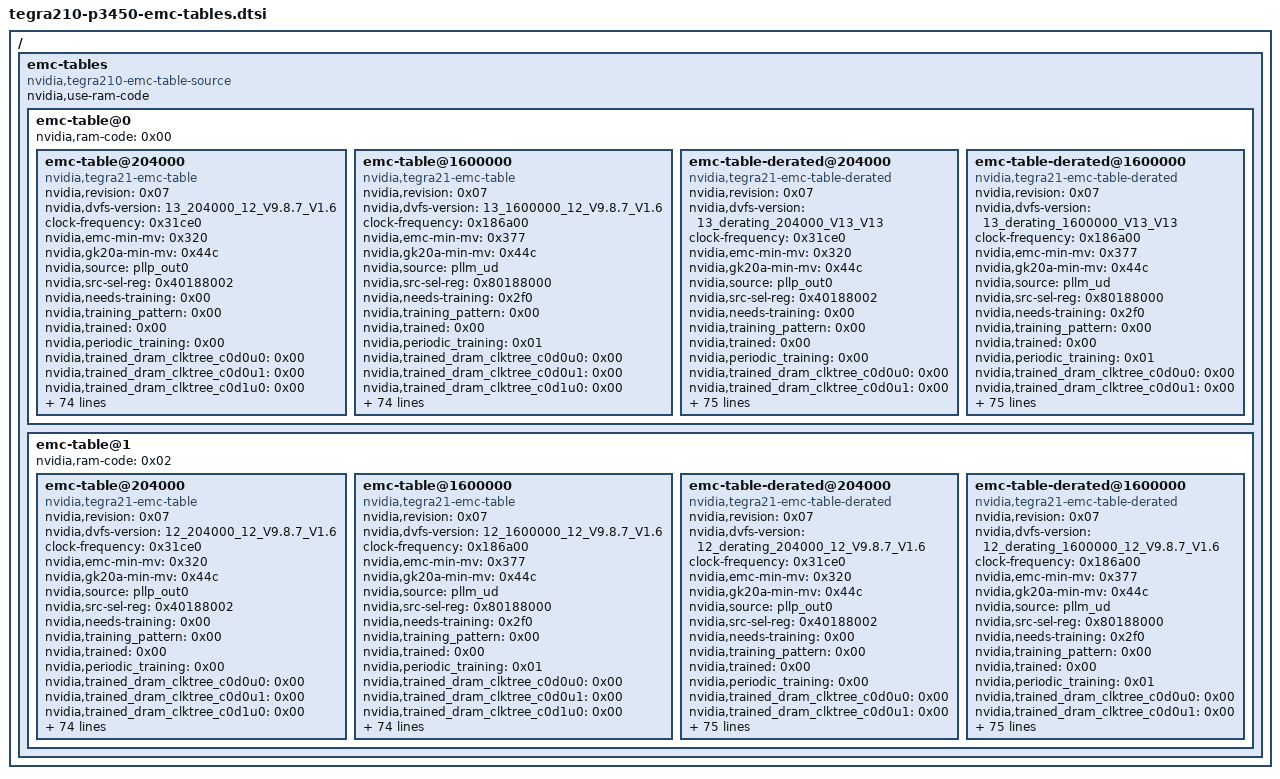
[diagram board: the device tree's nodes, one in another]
// SPDX-License-Identifier: GPL-2.0+
/*
 * Jetson Nano (P3450) EMC frequency tables, extracted verbatim from NVIDIA's
 * bl-dtb (the proprietary rp1 blob that cboot loads).  Carried in U-Boot's
 * control DTB so that, under the RAM-boot flow (cboot bypassed), U-Boot can
 * synthesize the binary EMC timing table the mainline tegra210-emc driver
 * expects and inject it + its reserved-memory carveout into the kernel DTB --
 * exactly what cboot does on a normal boot.  See board/nvidia/p3450-0000/emc-table.c.
 *
 * Nothing here is hand-authored: the emc-table@{0,1} subtrees (nominal +
 * derated, ram-code 0 and 2, each 204 MHz + 1600 MHz) are copied unchanged
 * from the stock bl-dtb.
 */

/ {
	emc-tables {
		compatible = "nvidia,tegra210-emc-table-source";
		nvidia,use-ram-code;

		emc-table@0 {
			nvidia,ram-code = <0x00>;

			emc-table@204000 {
				compatible = "nvidia,tegra21-emc-table";
				nvidia,revision = <0x07>;
				nvidia,dvfs-version = "13_204000_12_V9.8.7_V1.6";
				clock-frequency = <0x31ce0>;
				nvidia,emc-min-mv = <0x320>;
				nvidia,gk20a-min-mv = <0x44c>;
				nvidia,source = "pllp_out0";
				nvidia,src-sel-reg = <0x40188002>;
				nvidia,needs-training = <0x00>;
				nvidia,training_pattern = <0x00>;
				nvidia,trained = <0x00>;
				nvidia,periodic_training = <0x00>;
				nvidia,trained_dram_clktree_c0d0u0 = <0x00>;
				nvidia,trained_dram_clktree_c0d0u1 = <0x00>;
				nvidia,trained_dram_clktree_c0d1u0 = <0x00>;
				nvidia,trained_dram_clktree_c0d1u1 = <0x00>;
				nvidia,trained_dram_clktree_c1d0u0 = <0x00>;
				nvidia,trained_dram_clktree_c1d0u1 = <0x00>;
				nvidia,trained_dram_clktree_c1d1u0 = <0x00>;
				nvidia,trained_dram_clktree_c1d1u1 = <0x00>;
				nvidia,current_dram_clktree_c0d0u0 = <0x00>;
				nvidia,current_dram_clktree_c0d0u1 = <0x00>;
				nvidia,current_dram_clktree_c0d1u0 = <0x00>;
				nvidia,current_dram_clktree_c0d1u1 = <0x00>;
				nvidia,current_dram_clktree_c1d0u0 = <0x00>;
				nvidia,current_dram_clktree_c1d0u1 = <0x00>;
				nvidia,current_dram_clktree_c1d1u0 = <0x00>;
				nvidia,current_dram_clktree_c1d1u1 = <0x00>;
				nvidia,run_clocks = <0x0d>;
				nvidia,tree_margin = <0x01>;
				nvidia,burst-regs-num = <0xdd>;
				nvidia,burst-regs-per-ch-num = <0x08>;
				nvidia,trim-regs-num = <0x8a>;
				nvidia,trim-regs-per-ch-num = <0x0a>;
				nvidia,burst-mc-regs-num = <0x21>;
				nvidia,la-scale-regs-num = <0x18>;
				nvidia,vref-regs-num = <0x04>;
				nvidia,training-mod-regs-num = <0x14>;
				nvidia,dram-timing-regs-num = <0x05>;
				nvidia,min-mrs-wait = <0x16>;
				nvidia,emc-mrw = <0x88010004>;
				nvidia,emc-mrw2 = <0x88020000>;
				nvidia,emc-mrw3 = <0x880d0000>;
				nvidia,emc-mrw4 = <0xc0000000>;
				nvidia,emc-mrw9 = <0x8c0e7272>;
				nvidia,emc-mrs = <0x00>;
				nvidia,emc-emrs = <0x00>;
				nvidia,emc-emrs2 = <0x00>;
				nvidia,emc-auto-cal-config = <0xa01a51d8>;
				nvidia,emc-auto-cal-config2 = <0x5500000>;
				nvidia,emc-auto-cal-config3 = <0x770000>;
				nvidia,emc-auto-cal-config4 = <0x770000>;
				nvidia,emc-auto-cal-config5 = <0x770000>;
				nvidia,emc-auto-cal-config6 = <0x770000>;
				nvidia,emc-auto-cal-config7 = <0x770000>;
				nvidia,emc-auto-cal-config8 = <0x770000>;
				nvidia,emc-cfg-2 = <0x110805>;
				nvidia,emc-sel-dpd-ctrl = <0x40008>;
				nvidia,emc-fdpd-ctrl-cmd-no-ramp = <0x01>;
				nvidia,dll-clk-src = <0x40188002>;
				nvidia,clk-out-enb-x-0-clk-enb-emc-dll = <0x01>;
				nvidia,emc-clock-latency-change = <0xd5c>;
				nvidia,ptfv = <0x00 0x00 0x00 0x00 0x00 0x00 0x00 0x00 0x0a 0x0a 0x0a 0x01>;
				nvidia,emc-registers = <0x0d 0x3a 0x1d 0x00 0x00 0x09 0x04 0x0b 0x0d 0x08 0x0b 0x00 0x04 0x20 0x06 0x06 0x06 0x03 0x00 0x06 0x04 0x02 0x00 0x04 0x08 0x0d 0x06 0x05 0x00 0x00 0x03 0x88037171 0x0c 0x01 0x0a 0x10000 0x12 0x14 0x16 0x12 0x14 0x304 0x00 0xc1 0x08 0x08 0x03 0x03 0x03 0x14 0x05 0x02 0x0d 0x3b 0x3b 0x05 0x05 0x04 0x09 0x05 0x04 0x09 0xc8037171 0x31c 0x00 0x9160a00d 0x3bbf 0x2c00a0 0x8000 0xbe 0xfff0fff 0xfff0fff 0x00 0x00 0x00 0x00 0x880b0000 0xe0017 0x1c0014 0x450031 0x3f002b 0x3d0028 0x3d0031 0x0b 0x100004 0x450031 0x3f002b 0x3d0028 0x3d0031 0x0b 0x100004 0x170017 0xe000e 0x140014 0x1c001c 0x17 0x00 0x00 0x00 0x00 0x00 0x00 0x00 0x00 0x00 0x00 0x00 0x00 0x00 0x00 0x00 0x00 0x00 0x00 0x00 0x00 0x00 0x00 0x00 0x00 0x00 0x00 0x00 0x00 0x00 0x00 0x00 0x00 0x00 0x00 0x00 0x00 0x00 0x00 0x00 0x00 0x8020221f 0x220f40f 0x12 0x64000 0x900cc 0xcc0016 0x33000a 0xc1e00303 0x1f13412f 0x10014 0x804 0x550 0xf3200000 0xfff0fff 0x713 0x0a 0x00 0x00 0x1b 0x1b 0x20000 0x50037 0x00 0x10 0x3000 0xa000000 0x2000111 0x08 0x30808 0x15c00 0x101010 0x1600 0x00 0x00 0x00 0x34 0x40 0x18000800 0x8000800 0x8000800 0x8000800 0x400080 0x8801004 0x20 0x00 0x00 0x00 0x00 0x00 0x00 0xefffefff 0xc0c0c0c0 0xc0c0c0c0 0xdcdcdcdc 0xa0a0a0a 0xa0a0a0a 0xa0a0a0a 0x1186033 0x00 0x00 0x14 0x0a 0x16 0x88161414 0x12 0x10000 0x9080 0x7070404 0x40065 0x513801f 0x1f101100 0x14 0x107240 0x1124000 0x1125b6a 0xf081000 0x105800 0x1110fc00 0xf081300 0x105800 0x1114fc00 0x7000300 0x107240 0x55553c5a 0xc8161414>;
				nvidia,emc-burst-regs-per-ch = <0x880c7272 0x880c7272 0xc80c7272 0xc80c7272 0x8c0e7272 0x8c0e7272 0x4c0e7272 0x4c0e7272>;
				nvidia,emc-shadow-regs-ca-train = <0x0d 0x3a 0x1d 0x00 0x00 0x09 0x04 0x0b 0x0d 0x08 0x0b 0x00 0x04 0x20 0x06 0x06 0x06 0x03 0x00 0x06 0x04 0x02 0x00 0x04 0x08 0x0d 0x06 0x05 0x00 0x00 0x03 0x88037171 0x0c 0x01 0x0a 0x10000 0x12 0x14 0x16 0x12 0x14 0x304 0x00 0xc1 0x08 0x08 0x03 0x03 0x03 0x14 0x05 0x02 0x0d 0x3b 0x3b 0x05 0x05 0x04 0x09 0x05 0x04 0x09 0xc8037171 0x31c 0x00 0x9960a00d 0x3bbf 0x2c00a0 0x8000 0x55 0xfff0fff 0xfff0fff 0x00 0x00 0x00 0x00 0x880b0000 0xe0017 0x1c0014 0x450031 0x3f002b 0x3d0028 0x3d0031 0x0b 0x100004 0x450031 0x3f002b 0x3d0028 0x3d0031 0x0b 0x100004 0x170017 0xe000e 0x140014 0x1c001c 0x17 0x00 0x00 0x00 0x00 0x00 0x00 0x00 0x00 0x00 0x00 0x00 0x00 0x00 0x00 0x00 0x00 0x00 0x00 0x00 0x00 0x00 0x00 0x00 0x00 0x00 0x00 0x00 0x00 0x00 0x00 0x00 0x00 0x00 0x00 0x00 0x00 0x00 0x00 0x00 0x00 0x8020221f 0x220f40f 0x12 0x64000 0x900cc 0xcc0016 0x33000a 0xc1e00303 0x1f13412f 0x10014 0x804 0x550 0xf3200000 0xfff0fff 0x713 0x0a 0x00 0x00 0x1b 0x1b 0x20000 0x5058033 0x5050000 0x00 0x3000 0xa000000 0x2000111 0x08 0x30808 0x15c00 0x101010 0x1600 0x00 0x00 0x00 0x34 0x40 0x18000800 0x8000800 0x8000800 0x8000800 0x400080 0x8801004 0x20 0x00 0x00 0x00 0x00 0x00 0x00 0xefffefff 0xc0c0c0c0 0xc0c0c0c0 0xdcdcdcdc 0xa0a0a0a 0xa0a0a0a 0xa0a0a0a 0x1186033 0x01 0x1f 0x18 0x08 0x1a 0x88161414 0x10 0x10000 0x9080 0x7070404 0x40065 0x513801f 0x1f101100 0x14 0x107240 0x1124000 0x1125b6a 0xf081000 0x105800 0x1110fc00 0xf081300 0x105800 0x1114fc00 0x7000300 0x107240 0x55553c5a 0xc8161414>;
				nvidia,emc-shadow-regs-quse-train = <0x0d 0x3a 0x1d 0x00 0x00 0x09 0x04 0x0a 0x0d 0x08 0x0b 0x00 0x04 0x20 0x06 0x06 0x06 0x0c 0x00 0x06 0x04 0x02 0x00 0x04 0x08 0x0d 0x03 0x02 0x10000000 0x00 0x03 0x88037171 0x0b 0x01 0x80000000 0x40000 0x12 0x14 0x16 0x12 0x14 0x304 0x00 0xc1 0x08 0x08 0x03 0x03 0x03 0x14 0x05 0x02 0x0d 0x3b 0x3b 0x05 0x05 0x04 0x09 0x05 0x04 0x09 0xc8037171 0x31c 0x00 0x9160400d 0x3bbf 0x2c00a0 0x8000 0xbe 0xfff0fff 0xfff0fff 0x00 0x00 0x00 0x00 0x880b0000 0xe0017 0x1c0014 0x450031 0x3f002b 0x3d0028 0x3d0031 0x0b 0x100004 0x450031 0x3f002b 0x3d0028 0x3d0031 0x0b 0x100004 0x170017 0xe000e 0x140014 0x1c001c 0x17 0x00 0x00 0x00 0x00 0x00 0x00 0x00 0x00 0x00 0x00 0x00 0x00 0x00 0x00 0x00 0x00 0x00 0x00 0x00 0x00 0x00 0x00 0x00 0x00 0x00 0x00 0x00 0x00 0x00 0x00 0x00 0x00 0x00 0x00 0x00 0x00 0x00 0x00 0x00 0x00 0x8020221f 0x220f40f 0x12 0x64000 0x900cc 0xcc0016 0x33000a 0xc1e00303 0x1f13412f 0x10014 0x804 0x550 0xf3200000 0xfff0fff 0x713 0x0a 0x00 0x00 0x1b 0x1b 0x30020000 0x58037 0x00 0x10 0x3000 0xa000000 0x2000111 0x08 0x30808 0x15c00 0x101010 0x1600 0x00 0x00 0x00 0x34 0x40 0x18000800 0x8000800 0x8000800 0x8000800 0x400080 0x8801004 0x20 0x00 0x00 0x00 0x00 0x00 0x00 0xefffefff 0xc0c0c0c0 0xc0c0c0c0 0xdcdcdcdc 0xa0a0a0a 0xa0a0a0a 0xa0a0a0a 0x1186033 0x01 0x1f 0x1e 0x14 0x20 0x88161414 0x1c 0x40000 0x9080 0x7070404 0x40065 0x513801f 0x1f101100 0x14 0x107240 0x1124000 0x1125b6a 0xf081000 0x105800 0x1110fc00 0xf081300 0x105800 0x1114fc00 0x7000300 0x107240 0x55553c5a 0xc8161414>;
				nvidia,emc-shadow-regs-rdwr-train = <0x0d 0x3a 0x1d 0x00 0x00 0x09 0x04 0x0e 0x0d 0x08 0x0b 0x00 0x04 0x20 0x06 0x06 0x06 0x12 0x13 0x06 0x04 0x02 0x00 0x04 0x08 0x0d 0x06 0x05 0x10000000 0x30000002 0x03 0x88037171 0x0c 0x01 0x0a 0x40000 0x12 0x14 0x16 0x12 0x14 0x304 0x00 0xc1 0x08 0x08 0x03 0x03 0x03 0x14 0x05 0x02 0x0d 0x3b 0x3b 0x05 0x05 0x04 0x09 0x05 0x04 0x09 0xc8037171 0x31c 0x00 0x9160a00d 0x3bbf 0x2c00a0 0x8000 0xbe 0xfff0fff 0xfff0fff 0x00 0x00 0x00 0x00 0x880b0000 0xe0017 0x1c0014 0x450031 0x3f002b 0x3d0028 0x3d0031 0x0b 0x100004 0x450031 0x3f002b 0x3d0028 0x3d0031 0x0b 0x100004 0x170017 0xe000e 0x140014 0x1c001c 0x17 0x00 0x00 0x00 0x00 0x00 0x00 0x00 0x00 0x00 0x00 0x00 0x00 0x00 0x00 0x00 0x00 0x00 0x00 0x00 0x00 0x00 0x00 0x00 0x00 0x00 0x00 0x00 0x00 0x00 0x00 0x00 0x00 0x00 0x00 0x00 0x00 0x00 0x00 0x00 0x00 0x8020221f 0x220f40f 0x12 0x64000 0x900cc 0xcc0016 0x33000a 0xc1e00303 0x1f13412f 0x10014 0x804 0x550 0xf3200000 0xfff0fff 0x713 0x0a 0x00 0x00 0x1b 0x1b 0x20000 0x50037 0x00 0x10 0x3000 0xa000000 0x2000111 0x08 0x30808 0x15c00 0x101010 0x1600 0x00 0x00 0x00 0x34 0x40 0x18000800 0x8000800 0x8000800 0x8000800 0x400080 0x8801004 0x20 0x00 0x00 0x00 0x00 0x00 0x00 0xefffefff 0xc0c0c0c0 0xc0c0c0c0 0xdcdcdcdc 0xa0a0a0a 0xa0a0a0a 0xa0a0a0a 0x1186033 0x01 0x00 0x14 0x0a 0x16 0x88161414 0x12 0x40000 0xb080 0x7070404 0x40065 0x513801f 0x1f101100 0x14 0x107240 0x1124000 0x1125b6a 0xf081000 0x105800 0x1110fc00 0xf081300 0x105800 0x1114fc00 0x7000300 0x107240 0x55553c5a 0xc8161414>;
				nvidia,emc-trim-regs = <0x280028 0x280028 0x280028 0x280028 0x280028 0x280028 0x280028 0x280028 0x00 0x00 0x00 0x00 0x00 0x00 0x00 0x00 0x00 0x00 0x00 0x00 0x00 0x00 0x00 0x00 0x00 0x00 0x00 0x00 0x00 0x00 0x00 0x00 0x00 0x00 0x00 0x00 0x00 0x00 0x00 0x00 0x00 0x00 0x00 0x00 0x00 0x00 0x00 0x00 0x00 0x00 0x00 0x00 0x00 0x00 0x00 0x00 0x11111111 0x11111111 0x28282828 0x28282828 0x00 0x00 0x00 0x00 0xe0017 0x1c0014 0x00 0x00 0x00 0x00 0x00 0x00 0x00 0x00 0x00 0x00 0x00 0x00 0x00 0x00 0x00 0x00 0x00 0x00 0x00 0x00 0x00 0x00 0x00 0x00 0x00 0x00 0x00 0x00 0x00 0x00 0x00 0x00 0x00 0x00 0x00 0x00 0x00 0x00 0x00 0x00 0x00 0x00 0x00 0x00 0x00 0x00 0x00 0x00 0x00 0x00 0x00 0x00 0x00 0x00 0x00 0x00 0x00 0x00 0x00 0x00 0x00 0x00 0x00 0x00 0x00 0x00 0x00 0x00 0x00 0x00 0x00 0x00>;
				nvidia,emc-trim-regs-per-ch = <0x00 0x00 0x249249 0x249249 0x249249 0x249249 0x00 0x00 0x00 0x00>;
				nvidia,emc-vref-regs = <0x00 0x00 0x00 0x00>;
				nvidia,emc-dram-timing-regs = <0x12 0x104 0x118 0x18 0x06>;
				nvidia,emc-training-mod-regs = <0x00 0x00 0x00 0x00 0x00 0x00 0x00 0x00 0x00 0x00 0x00 0x00 0x00 0x00 0x00 0x00 0x00 0x00 0x00 0x00>;
				nvidia,emc-save-restore-mod-regs = <0x00 0x00 0x00 0x00 0x00 0x00 0x00 0x00 0x00 0x00 0x00 0x00>;
				nvidia,emc-burst-mc-regs = <0x8000001 0x8000004c 0xa1020 0x80001028 0x01 0x00 0x03 0x01 0x02 0x01 0x02 0x05 0x01 0x01 0x04 0x08 0x05 0x07 0x2020000 0x30201 0x72a30504 0x70000f0f 0x00 0x1f0000 0x80001a 0x80001a 0x80001a 0x80001a 0x80001a 0x80001a 0x80001a 0x80001a 0x80001a>;
				nvidia,emc-la-scale-regs = <0x1b 0x80001a 0x24c 0xff00b2 0xff00da 0xff009d 0xff00ff 0xff000c 0xff00ff 0xff000c 0x7f0049 0xff0080 0xff0004 0x800ad 0xff 0xff0004 0xff00c6 0xff00c6 0xff006d 0xff00ff 0xff00e2 0xff 0x80 0xff00ff>;
			};

			emc-table@1600000 {
				compatible = "nvidia,tegra21-emc-table";
				nvidia,revision = <0x07>;
				nvidia,dvfs-version = "13_1600000_12_V9.8.7_V1.6";
				clock-frequency = <0x186a00>;
				nvidia,emc-min-mv = <0x377>;
				nvidia,gk20a-min-mv = <0x44c>;
				nvidia,source = "pllm_ud";
				nvidia,src-sel-reg = <0x80188000>;
				nvidia,needs-training = <0x2f0>;
				nvidia,training_pattern = <0x00>;
				nvidia,trained = <0x00>;
				nvidia,periodic_training = <0x01>;
				nvidia,trained_dram_clktree_c0d0u0 = <0x00>;
				nvidia,trained_dram_clktree_c0d0u1 = <0x00>;
				nvidia,trained_dram_clktree_c0d1u0 = <0x00>;
				nvidia,trained_dram_clktree_c0d1u1 = <0x00>;
				nvidia,trained_dram_clktree_c1d0u0 = <0x00>;
				nvidia,trained_dram_clktree_c1d0u1 = <0x00>;
				nvidia,trained_dram_clktree_c1d1u0 = <0x00>;
				nvidia,trained_dram_clktree_c1d1u1 = <0x00>;
				nvidia,current_dram_clktree_c0d0u0 = <0x00>;
				nvidia,current_dram_clktree_c0d0u1 = <0x00>;
				nvidia,current_dram_clktree_c0d1u0 = <0x00>;
				nvidia,current_dram_clktree_c0d1u1 = <0x00>;
				nvidia,current_dram_clktree_c1d0u0 = <0x00>;
				nvidia,current_dram_clktree_c1d0u1 = <0x00>;
				nvidia,current_dram_clktree_c1d1u0 = <0x00>;
				nvidia,current_dram_clktree_c1d1u1 = <0x00>;
				nvidia,run_clocks = <0x40>;
				nvidia,tree_margin = <0x01>;
				nvidia,burst-regs-num = <0xdd>;
				nvidia,burst-regs-per-ch-num = <0x08>;
				nvidia,trim-regs-num = <0x8a>;
				nvidia,trim-regs-per-ch-num = <0x0a>;
				nvidia,burst-mc-regs-num = <0x21>;
				nvidia,la-scale-regs-num = <0x18>;
				nvidia,vref-regs-num = <0x04>;
				nvidia,training-mod-regs-num = <0x14>;
				nvidia,dram-timing-regs-num = <0x05>;
				nvidia,min-mrs-wait = <0x30>;
				nvidia,emc-mrw = <0x88010054>;
				nvidia,emc-mrw2 = <0x8802002d>;
				nvidia,emc-mrw3 = <0x880d0000>;
				nvidia,emc-mrw4 = <0xc0000000>;
				nvidia,emc-mrw9 = <0x8c0e4848>;
				nvidia,emc-mrs = <0x00>;
				nvidia,emc-emrs = <0x00>;
				nvidia,emc-emrs2 = <0x00>;
				nvidia,emc-auto-cal-config = <0xa01a51d8>;
				nvidia,emc-auto-cal-config2 = <0x5500000>;
				nvidia,emc-auto-cal-config3 = <0x770000>;
				nvidia,emc-auto-cal-config4 = <0x770000>;
				nvidia,emc-auto-cal-config5 = <0x770000>;
				nvidia,emc-auto-cal-config6 = <0x770000>;
				nvidia,emc-auto-cal-config7 = <0x770000>;
				nvidia,emc-auto-cal-config8 = <0x770000>;
				nvidia,emc-cfg-2 = <0x110835>;
				nvidia,emc-sel-dpd-ctrl = <0x40000>;
				nvidia,emc-fdpd-ctrl-cmd-no-ramp = <0x01>;
				nvidia,dll-clk-src = <0x80188000>;
				nvidia,clk-out-enb-x-0-clk-enb-emc-dll = <0x00>;
				nvidia,emc-clock-latency-change = <0x49c>;
				nvidia,ptfv = <0x00 0x00 0x00 0x00 0x00 0x00 0x00 0x00 0x0a 0x0a 0x0a 0x01>;
				nvidia,emc-registers = <0x60 0x1c0 0xe0 0x00 0x00 0x44 0x1d 0x29 0x21 0x0c 0x2d 0x00 0x04 0x20 0x1d 0x1d 0x10 0x17 0x16 0x06 0x0e 0x0c 0x0a 0x0e 0x08 0x0d 0x24 0x08 0x1000001c 0x10000002 0x14 0x8803f1f1 0x1c 0x1f 0x0d 0x6000c 0x33 0x3b 0x3d 0x39 0x3b 0x1820 0x00 0x608 0x10 0x10 0x03 0x03 0x03 0x38 0x0e 0x02 0x2e 0x1cc 0x1cc 0x0d 0x18 0x0c 0x40 0x22 0x04 0x14 0xc803f1f1 0x1860 0x00 0x9960a00d 0x3bff 0xc00001bb 0x8000 0x55 0x00 0x00 0x00 0x00 0x00 0x00 0x880b6666 0x8000e 0x11000c 0x1c001c 0x1c001c 0x1c001c 0x1c001c 0x07 0x90002 0x1c001c 0x1c001c 0x1c001c 0x1c001c 0x07 0x90002 0xe000e 0x80008 0xc000c 0x110011 0x0e 0x00 0x00 0x00 0x00 0x00 0x00 0x00 0x00 0x00 0x00 0x00 0x00 0x00 0x00 0x00 0x00 0x00 0x00 0x00 0x00 0x00 0x00 0x00 0x00 0x00 0x00 0x00 0x00 0x00 0x00 0x00 0x00 0x00 0x00 0x00 0x00 0x00 0x00 0x00 0x00 0x8020221f 0x220f40f 0x12 0x64000 0x310640 0x6400030 0x1900017 0xc1e0030a 0x1f13612f 0x14 0x80d 0x550 0xf3200000 0x00 0x308c 0x2b 0x00 0x00 0x1b 0x1b 0x20000 0x33 0x00 0x11 0x3000 0x2000000 0x2000101 0x07 0x30808 0x15c00 0x102020 0x1fff1fff 0x00 0x00 0x00 0x34 0x40 0x18000800 0x8000800 0x8000800 0x8000800 0x400080 0x8801004 0x20 0x00 0x00 0x00 0x00 0x00 0x00 0xefff2210 0x00 0x00 0xdcdcdcdc 0xa0a0a0a 0xa0a0a0a 0xa0a0a0a 0x1186190 0x00 0x00 0x3b 0x2b 0x3d 0x88161414 0x33 0x6000c 0x9080 0x7070404 0x40320 0x513801f 0x1f101100 0x14 0x103200 0x1124000 0x1125b6a 0xf081000 0x105800 0x1110fc00 0xf085300 0x105800 0x1114fc00 0x7004300 0x103200 0x55553c5a 0xc8161414>;
				nvidia,emc-burst-regs-per-ch = <0x880c4848 0x880c4848 0xc80c4848 0xc80c4848 0x8c0e4848 0x8c0e4848 0x4c0e4848 0x4c0e4848>;
				nvidia,emc-shadow-regs-ca-train = <0x60 0x1c0 0xe0 0x00 0x00 0x44 0x1d 0x29 0x21 0x0c 0x2d 0x00 0x04 0x20 0x1d 0x1d 0x10 0x17 0x16 0x06 0x0e 0x0c 0x0a 0x0e 0x08 0x0d 0x24 0x08 0x1000001c 0x10000002 0x14 0x8803f1f1 0x1c 0x1f 0x0d 0x6000c 0x33 0x3b 0x3d 0x39 0x3b 0x1820 0x00 0x608 0x10 0x10 0x03 0x03 0x03 0x38 0x0e 0x02 0x2e 0x1cc 0x1cc 0x0d 0x18 0x0c 0x40 0x22 0x04 0x14 0xc803f1f1 0x1860 0x00 0x9960a00d 0x3bff 0xc00001bb 0x8000 0x55 0x00 0x00 0x00 0x00 0x00 0x00 0x880b6666 0x8000e 0x11000c 0x1c001c 0x1c001c 0x1c001c 0x1c001c 0x07 0x90002 0x1c001c 0x1c001c 0x1c001c 0x1c001c 0x07 0x90002 0xe000e 0x80008 0xc000c 0x110011 0x0e 0x00 0x00 0x00 0x00 0x00 0x00 0x00 0x00 0x00 0x00 0x00 0x00 0x00 0x00 0x00 0x00 0x00 0x00 0x00 0x00 0x00 0x00 0x00 0x00 0x00 0x00 0x00 0x00 0x00 0x00 0x00 0x00 0x00 0x00 0x00 0x00 0x00 0x00 0x00 0x00 0x8020221f 0x220f40f 0x12 0x64000 0x310640 0x6400030 0x1900017 0xc1e0030a 0x1f13612f 0x14 0x80d 0x550 0xf3200000 0x00 0x308c 0x2b 0x00 0x00 0x1b 0x1b 0x20000 0x8033 0x00 0x00 0x3000 0x2000000 0x2000101 0x07 0x30808 0x15c00 0x102020 0x1fff1fff 0x00 0x00 0x00 0x34 0x40 0x18000800 0x8000800 0x8000800 0x8000800 0x400080 0x8801004 0x20 0x00 0x00 0x00 0x00 0x00 0x00 0xefff2210 0x00 0x00 0xdcdcdcdc 0xa0a0a0a 0xa0a0a0a 0xa0a0a0a 0x1186190 0x01 0x1f 0x41 0x2b 0x43 0x88161414 0x33 0x6000c 0x9080 0x7070404 0x40320 0x513801f 0x1f101100 0x14 0x103200 0x1124000 0x1125b6a 0xf081000 0x105800 0x1110fc00 0xf085300 0x105800 0x1114fc00 0x7004300 0x103200 0x55553c5a 0xc8161414>;
				nvidia,emc-shadow-regs-quse-train = <0x60 0x1c0 0xe0 0x00 0x00 0x44 0x1d 0x28 0x21 0x0c 0x2d 0x00 0x04 0x20 0x1d 0x1d 0x10 0x11 0x16 0x06 0x0e 0x0c 0x0a 0x0e 0x08 0x0d 0x21 0x02 0x1000001c 0x10000002 0x14 0x8803f1f1 0x1b 0x01 0x80000000 0x6000c 0x33 0x3b 0x3d 0x39 0x3b 0x1820 0x00 0x608 0x10 0x10 0x03 0x03 0x03 0x38 0x0e 0x02 0x2e 0x1cc 0x1cc 0x0d 0x18 0x0c 0x40 0x22 0x04 0x14 0xc803f1f1 0x1860 0x00 0x9960400d 0x3bff 0xc00001bb 0x8000 0x55 0x00 0x00 0x00 0x00 0x00 0x00 0x880b6666 0x8000e 0x11000c 0x1c001c 0x1c001c 0x1c001c 0x1c001c 0x07 0x90002 0x1c001c 0x1c001c 0x1c001c 0x1c001c 0x07 0x90002 0xe000e 0x80008 0xc000c 0x110011 0x0e 0x00 0x00 0x00 0x00 0x00 0x00 0x00 0x00 0x00 0x00 0x00 0x00 0x00 0x00 0x00 0x00 0x00 0x00 0x00 0x00 0x00 0x00 0x00 0x00 0x00 0x00 0x00 0x00 0x00 0x00 0x00 0x00 0x00 0x00 0x00 0x00 0x00 0x00 0x00 0x00 0x8020221f 0x220f40f 0x12 0x64000 0x310640 0x6400030 0x1900017 0xc1e0030a 0x1f13612f 0x14 0x80d 0x550 0xf3200000 0x00 0x308c 0x2b 0x00 0x00 0x1b 0x1b 0x30020000 0x8033 0x00 0x11 0x3000 0x2000000 0x2000101 0x07 0x30808 0x15c00 0x102020 0x1fff1fff 0x00 0x00 0x00 0x34 0x40 0x18000800 0x8000800 0x8000800 0x8000800 0x400080 0x8801004 0x20 0x00 0x00 0x00 0x00 0x00 0x00 0xefff2210 0x00 0x00 0xdcdcdcdc 0xa0a0a0a 0xa0a0a0a 0xa0a0a0a 0x1186190 0x01 0x1f 0x45 0x35 0x47 0x88161414 0x3d 0x6000c 0x9080 0x7070404 0x40320 0x513801f 0x1f101100 0x14 0x103200 0x1124000 0x1125b6a 0xf081000 0x105800 0x1110fc00 0xf085300 0x105800 0x1114fc00 0x7004300 0x103200 0x55553c5a 0xc8161414>;
				nvidia,emc-shadow-regs-rdwr-train = <0x60 0x1c0 0xe0 0x00 0x00 0x44 0x1d 0x29 0x21 0x0c 0x2d 0x00 0x04 0x20 0x1d 0x1d 0x10 0x17 0x16 0x06 0x0e 0x0c 0x0a 0x0e 0x08 0x0d 0x24 0x08 0x1000001c 0x10000002 0x14 0x8803f1f1 0x1c 0x1f 0x0d 0x6000c 0x33 0x3b 0x3d 0x39 0x3b 0x1820 0x00 0x608 0x10 0x10 0x03 0x03 0x03 0x38 0x0e 0x02 0x2e 0x1cc 0x1cc 0x0d 0x18 0x0c 0x40 0x22 0x04 0x14 0xc803f1f1 0x1860 0x00 0x9960a00d 0x3bff 0xc00001bb 0x8000 0x55 0x00 0x00 0x00 0x00 0x00 0x00 0x880b6666 0x8000e 0x11000c 0x1c001c 0x1c001c 0x1c001c 0x1c001c 0x07 0x90002 0x1c001c 0x1c001c 0x1c001c 0x1c001c 0x07 0x90002 0xe000e 0x80008 0xc000c 0x110011 0x0e 0x00 0x00 0x00 0x00 0x00 0x00 0x00 0x00 0x00 0x00 0x00 0x00 0x00 0x00 0x00 0x00 0x00 0x00 0x00 0x00 0x00 0x00 0x00 0x00 0x00 0x00 0x00 0x00 0x00 0x00 0x00 0x00 0x00 0x00 0x00 0x00 0x00 0x00 0x00 0x00 0x8020221f 0x220f40f 0x12 0x64000 0x310640 0x6400030 0x1900017 0xc1e0030a 0x1f13612f 0x14 0x80d 0x550 0xf3200000 0x00 0x308c 0x2b 0x00 0x00 0x1b 0x1b 0x20000 0x33 0x00 0x11 0x3000 0x2000000 0x2000101 0x07 0x30808 0x15c00 0x102020 0x1fff1fff 0x00 0x00 0x00 0x34 0x40 0x18000800 0x8000800 0x8000800 0x8000800 0x400080 0x8801004 0x20 0x00 0x00 0x00 0x00 0x00 0x00 0xefff2210 0x00 0x00 0xdcdcdcdc 0xa0a0a0a 0xa0a0a0a 0xa0a0a0a 0x1186190 0x01 0x00 0x3b 0x2b 0x3d 0x88161414 0x33 0x6000c 0xb080 0x7070404 0x40320 0x513801f 0x1f101100 0x14 0x103200 0x1124000 0x1125b6a 0xf081000 0x105800 0x1110fc00 0xf085300 0x105800 0x1114fc00 0x7004300 0x103200 0x55553c5a 0xc8161414>;
				nvidia,emc-trim-regs = <0x200020 0x200020 0x200020 0x200020 0x200020 0x200020 0x200020 0x200020 0x00 0x00 0x00 0x00 0x00 0x00 0x00 0x00 0x00 0x00 0x00 0x00 0x00 0x00 0x00 0x00 0x00 0x00 0x00 0x00 0x00 0x00 0x00 0x00 0x00 0x00 0x00 0x00 0x00 0x00 0x00 0x00 0x00 0x00 0x00 0x00 0x00 0x00 0x00 0x00 0x00 0x00 0x00 0x00 0x00 0x00 0x00 0x00 0x11111111 0x11111111 0x11111111 0x11111111 0x2b0022 0x2b0026 0x260025 0x260026 0x8000e 0x11000c 0x2b0022 0x2b0026 0x260025 0x260026 0x00 0x00 0x00 0x00 0x00 0x00 0x00 0x00 0x00 0x00 0x00 0x00 0x00 0x00 0x00 0x00 0x00 0x00 0x00 0x00 0x00 0x00 0x00 0x00 0x00 0x00 0x00 0x00 0x00 0x00 0x00 0x00 0x00 0x00 0x00 0x00 0x00 0x00 0x00 0x00 0x00 0x00 0x00 0x00 0x00 0x00 0x00 0x00 0x00 0x00 0x00 0x00 0x00 0x00 0x00 0x00 0x00 0x00 0x00 0x00 0x00 0x00 0x00 0x00 0x00 0x00 0x00 0x00>;
				nvidia,emc-trim-regs-per-ch = <0x00 0x00 0x00 0x00 0x00 0x00 0x00 0x00 0x00 0x00>;
				nvidia,emc-vref-regs = <0x00 0x00 0x00 0x00>;
				nvidia,emc-dram-timing-regs = <0x12 0x104 0x118 0x07 0x20>;
				nvidia,emc-training-mod-regs = <0x00 0x00 0x00 0x00 0x00 0x00 0x00 0x00 0x00 0x00 0x00 0x00 0x00 0x00 0x00 0x00 0x00 0x00 0x00 0x00>;
				nvidia,emc-save-restore-mod-regs = <0x00 0x00 0x00 0x00 0x00 0x00 0x00 0x00 0x04 0x04 0x04 0x04>;
				nvidia,emc-burst-mc-regs = <0x0c 0x80000080 0xa1020 0x80001028 0x06 0x07 0x18 0x0f 0x0f 0x03 0x03 0x0d 0x01 0x01 0x0c 0x08 0x0a 0x37 0x5060000 0xd080c 0x726c2419 0x70000f0f 0x00 0x1f0000 0x80001a 0x80001a 0x80001a 0x80001a 0x80001a 0x80001a 0x80001a 0x80001a 0x80001a>;
				nvidia,emc-la-scale-regs = <0xd0 0x80001a 0x1203 0x80003d 0x800038 0x800041 0x800090 0x800005 0x800090 0x800005 0x340049 0x800080 0x800004 0x80016 0x80 0x800004 0x800019 0x800019 0x800018 0x800095 0x80001d 0x80 0x2c 0x800080>;
			};

			emc-table-derated@204000 {
				compatible = "nvidia,tegra21-emc-table-derated";
				nvidia,revision = <0x07>;
				nvidia,dvfs-version = "13_derating_204000_V13_V13";
				clock-frequency = <0x31ce0>;
				nvidia,emc-min-mv = <0x320>;
				nvidia,gk20a-min-mv = <0x44c>;
				nvidia,source = "pllp_out0";
				nvidia,src-sel-reg = <0x40188002>;
				nvidia,needs-training = <0x00>;
				nvidia,training_pattern = <0x00>;
				nvidia,trained = <0x00>;
				nvidia,periodic_training = <0x00>;
				nvidia,trained_dram_clktree_c0d0u0 = <0x00>;
				nvidia,trained_dram_clktree_c0d0u1 = <0x00>;
				nvidia,trained_dram_clktree_c0d1u0 = <0x00>;
				nvidia,trained_dram_clktree_c0d1u1 = <0x00>;
				nvidia,trained_dram_clktree_c1d0u0 = <0x00>;
				nvidia,trained_dram_clktree_c1d0u1 = <0x00>;
				nvidia,trained_dram_clktree_c1d1u0 = <0x00>;
				nvidia,trained_dram_clktree_c1d1u1 = <0x00>;
				nvidia,current_dram_clktree_c0d0u0 = <0x00>;
				nvidia,current_dram_clktree_c0d0u1 = <0x00>;
				nvidia,current_dram_clktree_c0d1u0 = <0x00>;
				nvidia,current_dram_clktree_c0d1u1 = <0x00>;
				nvidia,current_dram_clktree_c1d0u0 = <0x00>;
				nvidia,current_dram_clktree_c1d0u1 = <0x00>;
				nvidia,current_dram_clktree_c1d1u0 = <0x00>;
				nvidia,current_dram_clktree_c1d1u1 = <0x00>;
				nvidia,run_clocks = <0x0d>;
				nvidia,tree_margin = <0x01>;
				nvidia,burst-regs-num = <0xdd>;
				nvidia,burst-regs-per-ch-num = <0x08>;
				nvidia,trim-regs-num = <0x8a>;
				nvidia,trim-regs-per-ch-num = <0x0a>;
				nvidia,burst-mc-regs-num = <0x21>;
				nvidia,la-scale-regs-num = <0x18>;
				nvidia,vref-regs-num = <0x04>;
				nvidia,training-mod-regs-num = <0x14>;
				nvidia,dram-timing-regs-num = <0x05>;
				nvidia,min-mrs-wait = <0x16>;
				nvidia,emc-mrw = <0x88010004>;
				nvidia,emc-mrw2 = <0x88020000>;
				nvidia,emc-mrw3 = <0x880d0000>;
				nvidia,emc-mrw4 = <0xc0000000>;
				nvidia,emc-mrw9 = <0x8c0e7272>;
				nvidia,emc-mrs = <0x00>;
				nvidia,emc-emrs = <0x00>;
				nvidia,emc-emrs2 = <0x00>;
				nvidia,emc-auto-cal-config = <0xa01a51d8>;
				nvidia,emc-auto-cal-config2 = <0x5500000>;
				nvidia,emc-auto-cal-config3 = <0x770000>;
				nvidia,emc-auto-cal-config4 = <0x770000>;
				nvidia,emc-auto-cal-config5 = <0x770000>;
				nvidia,emc-auto-cal-config6 = <0x770000>;
				nvidia,emc-auto-cal-config7 = <0x770000>;
				nvidia,emc-auto-cal-config8 = <0x770000>;
				nvidia,emc-cfg-2 = <0x110805>;
				nvidia,emc-sel-dpd-ctrl = <0x40008>;
				nvidia,emc-fdpd-ctrl-cmd-no-ramp = <0x01>;
				nvidia,dll-clk-src = <0x40188002>;
				nvidia,clk-out-enb-x-0-clk-enb-emc-dll = <0x01>;
				nvidia,emc-clock-latency-change = <0xd5c>;
				nvidia,ptfv = <0x00 0x00 0x00 0x00 0x00 0x00 0x00 0x00 0x0a 0x0a 0x0a 0x01>;
				nvidia,emc-registers = <0x0d 0x3a 0x1d 0x00 0x00 0x09 0x05 0x0b 0x0d 0x08 0x0b 0x00 0x04 0x20 0x06 0x06 0x06 0x03 0x00 0x06 0x04 0x02 0x00 0x04 0x08 0x0d 0x05 0x06 0x00 0x00 0x02 0x88037171 0x0d 0x00 0x0b 0x10000 0x12 0x14 0x16 0x12 0x14 0xc1 0x00 0x30 0x08 0x08 0x03 0x03 0x03 0x14 0x05 0x02 0x0e 0x3b 0x3b 0x05 0x05 0x04 0x09 0x05 0x04 0x09 0xc8037171 0x31c 0x00 0x9160a00d 0x3bbf 0x2c00a0 0x8000 0xbe 0xfff0fff 0xfff0fff 0x00 0x00 0x00 0x00 0x880b0000 0xe0017 0x1c0014 0x450031 0x3f002b 0x3d0028 0x3d0031 0x0b 0x100004 0x450031 0x3f002b 0x3d0028 0x3d0031 0x0b 0x100004 0x170017 0xe000e 0x140014 0x1c001c 0x17 0x00 0x00 0x00 0x00 0x00 0x00 0x00 0x00 0x00 0x00 0x00 0x00 0x00 0x00 0x00 0x00 0x00 0x00 0x00 0x00 0x00 0x00 0x00 0x00 0x00 0x00 0x00 0x00 0x00 0x00 0x00 0x00 0x00 0x00 0x00 0x00 0x00 0x00 0x00 0x00 0x8020221f 0x220f40f 0x12 0x64000 0x900cc 0xcc0016 0x33000a 0xc1e00303 0x1f13412f 0x10014 0x804 0x550 0xf3200000 0xfff0fff 0x287 0x0a 0x00 0x00 0x1b 0x1b 0x20000 0x50037 0x00 0x10 0x3000 0xa000000 0x2000111 0x08 0x30808 0x15c00 0x101010 0x1600 0x00 0x00 0x00 0x34 0x40 0x18000800 0x8000800 0x8000800 0x8000800 0x400080 0x8801004 0x20 0x00 0x00 0x00 0x00 0x00 0x00 0xefffefff 0xc0c0c0c0 0xc0c0c0c0 0xdcdcdcdc 0xa0a0a0a 0xa0a0a0a 0xa0a0a0a 0x1186033 0x00 0x00 0x14 0x0a 0x16 0x88161414 0x12 0x10000 0x9080 0x7070404 0x40065 0x513801f 0x1f101100 0x14 0x107240 0x1124000 0x1125b6a 0xf081000 0x105800 0x1110fc00 0xf081300 0x105800 0x1114fc00 0x7000300 0x107240 0x55553c5a 0xc8161414>;
				nvidia,emc-burst-regs-per-ch = <0x880c7272 0x880c7272 0xc80c7272 0xc80c7272 0x8c0e7272 0x8c0e7272 0x4c0e7272 0x4c0e7272>;
				nvidia,emc-shadow-regs-ca-train = <0x0d 0x3a 0x1d 0x00 0x00 0x09 0x05 0x0b 0x0d 0x08 0x0b 0x00 0x04 0x20 0x06 0x06 0x06 0x03 0x00 0x06 0x04 0x02 0x00 0x04 0x08 0x0d 0x05 0x06 0x00 0x00 0x02 0x88037171 0x0d 0x00 0x0b 0x10000 0x12 0x14 0x16 0x12 0x14 0xc1 0x00 0x30 0x08 0x08 0x03 0x03 0x03 0x14 0x05 0x02 0x0e 0x3b 0x3b 0x05 0x05 0x04 0x09 0x05 0x04 0x09 0xc8037171 0x31c 0x00 0x9960a00d 0x3bbf 0x2c00a0 0x8000 0x55 0xfff0fff 0xfff0fff 0x00 0x00 0x00 0x00 0x880b0000 0xe0017 0x1c0014 0x450031 0x3f002b 0x3d0028 0x3d0031 0x0b 0x100004 0x450031 0x3f002b 0x3d0028 0x3d0031 0x0b 0x100004 0x170017 0xe000e 0x140014 0x1c001c 0x17 0x00 0x00 0x00 0x00 0x00 0x00 0x00 0x00 0x00 0x00 0x00 0x00 0x00 0x00 0x00 0x00 0x00 0x00 0x00 0x00 0x00 0x00 0x00 0x00 0x00 0x00 0x00 0x00 0x00 0x00 0x00 0x00 0x00 0x00 0x00 0x00 0x00 0x00 0x00 0x00 0x8020221f 0x220f40f 0x12 0x64000 0x900cc 0xcc0016 0x33000a 0xc1e00303 0x1f13412f 0x10014 0x804 0x550 0xf3200000 0xfff0fff 0x287 0x0a 0x00 0x00 0x1b 0x1b 0x20000 0x5058033 0x5050000 0x00 0x3000 0xa000000 0x2000111 0x08 0x30808 0x15c00 0x101010 0x1600 0x00 0x00 0x00 0x34 0x40 0x18000800 0x8000800 0x8000800 0x8000800 0x400080 0x8801004 0x20 0x00 0x00 0x00 0x00 0x00 0x00 0xefffefff 0xc0c0c0c0 0xc0c0c0c0 0xdcdcdcdc 0xa0a0a0a 0xa0a0a0a 0xa0a0a0a 0x1186033 0x01 0x1f 0x18 0x08 0x1a 0x88161414 0x10 0x10000 0x9080 0x7070404 0x40065 0x513801f 0x1f101100 0x14 0x107240 0x1124000 0x1125b6a 0xf081000 0x105800 0x1110fc00 0xf081300 0x105800 0x1114fc00 0x7000300 0x107240 0x55553c5a 0xc8161414>;
				nvidia,emc-shadow-regs-quse-train = <0x0d 0x3a 0x1d 0x00 0x00 0x09 0x05 0x0a 0x0d 0x08 0x0b 0x00 0x04 0x20 0x06 0x06 0x06 0x0c 0x00 0x06 0x04 0x02 0x00 0x04 0x08 0x0d 0x03 0x02 0x10000000 0x00 0x03 0x88037171 0x0b 0x01 0x80000000 0x40000 0x12 0x14 0x16 0x12 0x14 0xc1 0x00 0x30 0x08 0x08 0x03 0x03 0x03 0x14 0x05 0x02 0x0e 0x3b 0x3b 0x05 0x05 0x04 0x09 0x05 0x04 0x09 0xc8037171 0x31c 0x00 0x9160400d 0x3bbf 0x2c00a0 0x8000 0xbe 0xfff0fff 0xfff0fff 0x00 0x00 0x00 0x00 0x880b0000 0xe0017 0x1c0014 0x450031 0x3f002b 0x3d0028 0x3d0031 0x0b 0x100004 0x450031 0x3f002b 0x3d0028 0x3d0031 0x0b 0x100004 0x170017 0xe000e 0x140014 0x1c001c 0x17 0x00 0x00 0x00 0x00 0x00 0x00 0x00 0x00 0x00 0x00 0x00 0x00 0x00 0x00 0x00 0x00 0x00 0x00 0x00 0x00 0x00 0x00 0x00 0x00 0x00 0x00 0x00 0x00 0x00 0x00 0x00 0x00 0x00 0x00 0x00 0x00 0x00 0x00 0x00 0x00 0x8020221f 0x220f40f 0x12 0x64000 0x900cc 0xcc0016 0x33000a 0xc1e00303 0x1f13412f 0x10014 0x804 0x550 0xf3200000 0xfff0fff 0x287 0x0a 0x00 0x00 0x1b 0x1b 0x30020000 0x58037 0x00 0x10 0x3000 0xa000000 0x2000111 0x08 0x30808 0x15c00 0x101010 0x1600 0x00 0x00 0x00 0x34 0x40 0x18000800 0x8000800 0x8000800 0x8000800 0x400080 0x8801004 0x20 0x00 0x00 0x00 0x00 0x00 0x00 0xefffefff 0xc0c0c0c0 0xc0c0c0c0 0xdcdcdcdc 0xa0a0a0a 0xa0a0a0a 0xa0a0a0a 0x1186033 0x01 0x1f 0x1e 0x14 0x20 0x88161414 0x1c 0x40000 0x9080 0x7070404 0x40065 0x513801f 0x1f101100 0x14 0x107240 0x1124000 0x1125b6a 0xf081000 0x105800 0x1110fc00 0xf081300 0x105800 0x1114fc00 0x7000300 0x107240 0x55553c5a 0xc8161414>;
				nvidia,emc-shadow-regs-rdwr-train = <0x0d 0x3a 0x1d 0x00 0x00 0x09 0x05 0x0e 0x0d 0x08 0x0b 0x00 0x04 0x20 0x06 0x06 0x06 0x13 0x13 0x06 0x04 0x02 0x00 0x04 0x08 0x0d 0x05 0x06 0x30000000 0x30000002 0x02 0x88037171 0x0d 0x00 0x0b 0x40000 0x12 0x14 0x16 0x12 0x14 0xc1 0x00 0x30 0x08 0x08 0x03 0x03 0x03 0x14 0x05 0x02 0x0e 0x3b 0x3b 0x05 0x05 0x04 0x09 0x05 0x04 0x09 0xc8037171 0x31c 0x00 0x9160a00d 0x3bbf 0x2c00a0 0x8000 0xbe 0xfff0fff 0xfff0fff 0x00 0x00 0x00 0x00 0x880b0000 0xe0017 0x1c0014 0x450031 0x3f002b 0x3d0028 0x3d0031 0x0b 0x100004 0x450031 0x3f002b 0x3d0028 0x3d0031 0x0b 0x100004 0x170017 0xe000e 0x140014 0x1c001c 0x17 0x00 0x00 0x00 0x00 0x00 0x00 0x00 0x00 0x00 0x00 0x00 0x00 0x00 0x00 0x00 0x00 0x00 0x00 0x00 0x00 0x00 0x00 0x00 0x00 0x00 0x00 0x00 0x00 0x00 0x00 0x00 0x00 0x00 0x00 0x00 0x00 0x00 0x00 0x00 0x00 0x8020221f 0x220f40f 0x12 0x64000 0x900cc 0xcc0016 0x33000a 0xc1e00303 0x1f13412f 0x10014 0x804 0x550 0xf3200000 0xfff0fff 0x287 0x0a 0x00 0x00 0x1b 0x1b 0x20000 0x50037 0x00 0x10 0x3000 0xa000000 0x2000111 0x08 0x30808 0x15c00 0x101010 0x1600 0x00 0x00 0x00 0x34 0x40 0x18000800 0x8000800 0x8000800 0x8000800 0x400080 0x8801004 0x20 0x00 0x00 0x00 0x00 0x00 0x00 0xefffefff 0xc0c0c0c0 0xc0c0c0c0 0xdcdcdcdc 0xa0a0a0a 0xa0a0a0a 0xa0a0a0a 0x1186033 0x01 0x00 0x14 0x0a 0x16 0x88161414 0x12 0x40000 0xb080 0x7070404 0x40065 0x513801f 0x1f101100 0x14 0x107240 0x1124000 0x1125b6a 0xf081000 0x105800 0x1110fc00 0xf081300 0x105800 0x1114fc00 0x7000300 0x107240 0x55553c5a 0xc8161414>;
				nvidia,emc-trim-regs = <0x280028 0x280028 0x280028 0x280028 0x280028 0x280028 0x280028 0x280028 0x00 0x00 0x00 0x00 0x00 0x00 0x00 0x00 0x00 0x00 0x00 0x00 0x00 0x00 0x00 0x00 0x00 0x00 0x00 0x00 0x00 0x00 0x00 0x00 0x00 0x00 0x00 0x00 0x00 0x00 0x00 0x00 0x00 0x00 0x00 0x00 0x00 0x00 0x00 0x00 0x00 0x00 0x00 0x00 0x00 0x00 0x00 0x00 0x11111111 0x11111111 0x28282828 0x28282828 0x00 0x00 0x00 0x00 0xe0017 0x1c0014 0x00 0x00 0x00 0x00 0x00 0x00 0x00 0x00 0x00 0x00 0x00 0x00 0x00 0x00 0x00 0x00 0x00 0x00 0x00 0x00 0x00 0x00 0x00 0x00 0x00 0x00 0x00 0x00 0x00 0x00 0x00 0x00 0x00 0x00 0x00 0x00 0x00 0x00 0x00 0x00 0x00 0x00 0x00 0x00 0x00 0x00 0x00 0x00 0x00 0x00 0x00 0x00 0x00 0x00 0x00 0x00 0x00 0x00 0x00 0x00 0x00 0x00 0x00 0x00 0x00 0x00 0x00 0x00 0x00 0x00 0x00 0x00>;
				nvidia,emc-trim-regs-per-ch = <0x00 0x00 0x249249 0x249249 0x249249 0x249249 0x00 0x00 0x00 0x00>;
				nvidia,emc-vref-regs = <0x00 0x00 0x00 0x00>;
				nvidia,emc-dram-timing-regs = <0x13 0x104 0x118 0x18 0x06>;
				nvidia,emc-training-mod-regs = <0x00 0x00 0x00 0x00 0x00 0x00 0x00 0x00 0x00 0x00 0x00 0x00 0x00 0x00 0x00 0x00 0x00 0x00 0x00 0x00>;
				nvidia,emc-save-restore-mod-regs = <0x00 0x00 0x00 0x00 0x00 0x00 0x00 0x00 0x00 0x00 0x00 0x00>;
				nvidia,emc-burst-mc-regs = <0x8000001 0x8000004c 0xa1020 0x80001028 0x01 0x01 0x03 0x01 0x02 0x01 0x02 0x04 0x01 0x01 0x04 0x08 0x05 0x07 0x2020000 0x30201 0x72a30504 0x70000f0f 0x00 0x1f0000 0x80001a 0x80001a 0x80001a 0x80001a 0x80001a 0x80001a 0x80001a 0x80001a 0x80001a>;
				nvidia,emc-la-scale-regs = <0x1b 0x80001a 0x24c 0xff00b2 0xff00da 0xff009d 0xff00ff 0xff000c 0xff00ff 0xff000c 0x7f0049 0xff0080 0xff0004 0x800ad 0xff 0xff0004 0xff00c6 0xff00c6 0xff006d 0xff00ff 0xff00e2 0xff 0x80 0xff00ff>;
			};

			emc-table-derated@1600000 {
				compatible = "nvidia,tegra21-emc-table-derated";
				nvidia,revision = <0x07>;
				nvidia,dvfs-version = "13_derating_1600000_V13_V13";
				clock-frequency = <0x186a00>;
				nvidia,emc-min-mv = <0x377>;
				nvidia,gk20a-min-mv = <0x44c>;
				nvidia,source = "pllm_ud";
				nvidia,src-sel-reg = <0x80188000>;
				nvidia,needs-training = <0x2f0>;
				nvidia,training_pattern = <0x00>;
				nvidia,trained = <0x00>;
				nvidia,periodic_training = <0x01>;
				nvidia,trained_dram_clktree_c0d0u0 = <0x00>;
				nvidia,trained_dram_clktree_c0d0u1 = <0x00>;
				nvidia,trained_dram_clktree_c0d1u0 = <0x00>;
				nvidia,trained_dram_clktree_c0d1u1 = <0x00>;
				nvidia,trained_dram_clktree_c1d0u0 = <0x00>;
				nvidia,trained_dram_clktree_c1d0u1 = <0x00>;
				nvidia,trained_dram_clktree_c1d1u0 = <0x00>;
				nvidia,trained_dram_clktree_c1d1u1 = <0x00>;
				nvidia,current_dram_clktree_c0d0u0 = <0x00>;
				nvidia,current_dram_clktree_c0d0u1 = <0x00>;
				nvidia,current_dram_clktree_c0d1u0 = <0x00>;
				nvidia,current_dram_clktree_c0d1u1 = <0x00>;
				nvidia,current_dram_clktree_c1d0u0 = <0x00>;
				nvidia,current_dram_clktree_c1d0u1 = <0x00>;
				nvidia,current_dram_clktree_c1d1u0 = <0x00>;
				nvidia,current_dram_clktree_c1d1u1 = <0x00>;
				nvidia,run_clocks = <0x40>;
				nvidia,tree_margin = <0x01>;
				nvidia,burst-regs-num = <0xdd>;
				nvidia,burst-regs-per-ch-num = <0x08>;
				nvidia,trim-regs-num = <0x8a>;
				nvidia,trim-regs-per-ch-num = <0x0a>;
				nvidia,burst-mc-regs-num = <0x21>;
				nvidia,la-scale-regs-num = <0x18>;
				nvidia,vref-regs-num = <0x04>;
				nvidia,training-mod-regs-num = <0x14>;
				nvidia,dram-timing-regs-num = <0x05>;
				nvidia,min-mrs-wait = <0x30>;
				nvidia,emc-mrw = <0x88010054>;
				nvidia,emc-mrw2 = <0x8802002d>;
				nvidia,emc-mrw3 = <0x880d0000>;
				nvidia,emc-mrw4 = <0xc0000000>;
				nvidia,emc-mrw9 = <0x8c0e4848>;
				nvidia,emc-mrs = <0x00>;
				nvidia,emc-emrs = <0x00>;
				nvidia,emc-emrs2 = <0x00>;
				nvidia,emc-auto-cal-config = <0xa01a51d8>;
				nvidia,emc-auto-cal-config2 = <0x5500000>;
				nvidia,emc-auto-cal-config3 = <0x770000>;
				nvidia,emc-auto-cal-config4 = <0x770000>;
				nvidia,emc-auto-cal-config5 = <0x770000>;
				nvidia,emc-auto-cal-config6 = <0x770000>;
				nvidia,emc-auto-cal-config7 = <0x770000>;
				nvidia,emc-auto-cal-config8 = <0x770000>;
				nvidia,emc-cfg-2 = <0x110835>;
				nvidia,emc-sel-dpd-ctrl = <0x40000>;
				nvidia,emc-fdpd-ctrl-cmd-no-ramp = <0x01>;
				nvidia,dll-clk-src = <0x80188000>;
				nvidia,clk-out-enb-x-0-clk-enb-emc-dll = <0x00>;
				nvidia,emc-clock-latency-change = <0x49c>;
				nvidia,ptfv = <0x00 0x00 0x00 0x00 0x00 0x00 0x00 0x00 0x0a 0x0a 0x0a 0x01>;
				nvidia,emc-registers = <0x66 0x1c0 0xe0 0x00 0x00 0x47 0x20 0x29 0x21 0x0c 0x2d 0x00 0x04 0x20 0x20 0x20 0x13 0x17 0x16 0x06 0x0e 0x0c 0x0a 0x0e 0x08 0x0d 0x24 0x08 0x1000001c 0x10000002 0x14 0x8803f1f1 0x1c 0x1f 0x0d 0x6000c 0x33 0x3b 0x3d 0x39 0x3b 0x5e9 0x00 0x17a 0x10 0x10 0x03 0x03 0x03 0x38 0x0e 0x02 0x31 0x1cc 0x1cc 0x0d 0x18 0x0c 0x40 0x25 0x04 0x14 0xc803f1f1 0x1860 0x00 0x9960a00d 0x3bff 0xc00001bb 0x8000 0x55 0x00 0x00 0x00 0x00 0x00 0x00 0x880b6666 0x8000e 0x11000c 0x1c001c 0x1c001c 0x1c001c 0x1c001c 0x07 0x90002 0x1c001c 0x1c001c 0x1c001c 0x1c001c 0x07 0x90002 0xe000e 0x80008 0xc000c 0x110011 0x0e 0x00 0x00 0x00 0x00 0x00 0x00 0x00 0x00 0x00 0x00 0x00 0x00 0x00 0x00 0x00 0x00 0x00 0x00 0x00 0x00 0x00 0x00 0x00 0x00 0x00 0x00 0x00 0x00 0x00 0x00 0x00 0x00 0x00 0x00 0x00 0x00 0x00 0x00 0x00 0x00 0x8020221f 0x220f40f 0x12 0x64000 0x310640 0x6400030 0x1900017 0xc1e0030a 0x1f13612f 0x14 0x80d 0x550 0xf3200000 0x00 0xce6 0x2b 0x00 0x00 0x1b 0x1b 0x20000 0x33 0x00 0x11 0x3000 0x2000000 0x2000101 0x07 0x30808 0x15c00 0x102020 0x1fff1fff 0x00 0x00 0x00 0x34 0x40 0x18000800 0x8000800 0x8000800 0x8000800 0x400080 0x8801004 0x20 0x00 0x00 0x00 0x00 0x00 0x00 0xefff2210 0x00 0x00 0xdcdcdcdc 0xa0a0a0a 0xa0a0a0a 0xa0a0a0a 0x1186190 0x00 0x00 0x3b 0x2b 0x3d 0x88161414 0x33 0x6000c 0x9080 0x7070404 0x40320 0x513801f 0x1f101100 0x14 0x103200 0x1124000 0x1125b6a 0xf081000 0x105800 0x1110fc00 0xf085300 0x105800 0x1114fc00 0x7004300 0x103200 0x55553c5a 0xc8161414>;
				nvidia,emc-burst-regs-per-ch = <0x880c4848 0x880c4848 0xc80c4848 0xc80c4848 0x8c0e4848 0x8c0e4848 0x4c0e4848 0x4c0e4848>;
				nvidia,emc-shadow-regs-ca-train = <0x66 0x1c0 0xe0 0x00 0x00 0x47 0x20 0x29 0x21 0x0c 0x2d 0x00 0x04 0x20 0x20 0x20 0x13 0x17 0x16 0x06 0x0e 0x0c 0x0a 0x0e 0x08 0x0d 0x24 0x08 0x1000001c 0x10000002 0x14 0x8803f1f1 0x1c 0x1f 0x0d 0x6000c 0x33 0x3b 0x3d 0x39 0x3b 0x5e9 0x00 0x17a 0x10 0x10 0x03 0x03 0x03 0x38 0x0e 0x02 0x31 0x1cc 0x1cc 0x0d 0x18 0x0c 0x40 0x25 0x04 0x14 0xc803f1f1 0x1860 0x00 0x9960a00d 0x3bff 0xc00001bb 0x8000 0x55 0x00 0x00 0x00 0x00 0x00 0x00 0x880b6666 0x8000e 0x11000c 0x1c001c 0x1c001c 0x1c001c 0x1c001c 0x07 0x90002 0x1c001c 0x1c001c 0x1c001c 0x1c001c 0x07 0x90002 0xe000e 0x80008 0xc000c 0x110011 0x0e 0x00 0x00 0x00 0x00 0x00 0x00 0x00 0x00 0x00 0x00 0x00 0x00 0x00 0x00 0x00 0x00 0x00 0x00 0x00 0x00 0x00 0x00 0x00 0x00 0x00 0x00 0x00 0x00 0x00 0x00 0x00 0x00 0x00 0x00 0x00 0x00 0x00 0x00 0x00 0x00 0x8020221f 0x220f40f 0x12 0x64000 0x310640 0x6400030 0x1900017 0xc1e0030a 0x1f13612f 0x14 0x80d 0x550 0xf3200000 0x00 0xce6 0x2b 0x00 0x00 0x1b 0x1b 0x20000 0x8033 0x00 0x00 0x3000 0x2000000 0x2000101 0x07 0x30808 0x15c00 0x102020 0x1fff1fff 0x00 0x00 0x00 0x34 0x40 0x18000800 0x8000800 0x8000800 0x8000800 0x400080 0x8801004 0x20 0x00 0x00 0x00 0x00 0x00 0x00 0xefff2210 0x00 0x00 0xdcdcdcdc 0xa0a0a0a 0xa0a0a0a 0xa0a0a0a 0x1186190 0x01 0x1f 0x41 0x2b 0x43 0x88161414 0x33 0x6000c 0x9080 0x7070404 0x40320 0x513801f 0x1f101100 0x14 0x103200 0x1124000 0x1125b6a 0xf081000 0x105800 0x1110fc00 0xf085300 0x105800 0x1114fc00 0x7004300 0x103200 0x55553c5a 0xc8161414>;
				nvidia,emc-shadow-regs-quse-train = <0x66 0x1c0 0xe0 0x00 0x00 0x47 0x20 0x28 0x21 0x0c 0x2d 0x00 0x04 0x20 0x20 0x20 0x13 0x11 0x16 0x06 0x0e 0x0c 0x0a 0x0e 0x08 0x0d 0x21 0x02 0x1000001c 0x10000002 0x14 0x8803f1f1 0x1b 0x01 0x80000000 0x6000c 0x33 0x3b 0x3d 0x39 0x3b 0x5e9 0x00 0x17a 0x10 0x10 0x03 0x03 0x03 0x38 0x0e 0x02 0x31 0x1cc 0x1cc 0x0d 0x18 0x0c 0x40 0x25 0x04 0x14 0xc803f1f1 0x1860 0x00 0x9960400d 0x3bff 0xc00001bb 0x8000 0x55 0x00 0x00 0x00 0x00 0x00 0x00 0x880b6666 0x8000e 0x11000c 0x1c001c 0x1c001c 0x1c001c 0x1c001c 0x07 0x90002 0x1c001c 0x1c001c 0x1c001c 0x1c001c 0x07 0x90002 0xe000e 0x80008 0xc000c 0x110011 0x0e 0x00 0x00 0x00 0x00 0x00 0x00 0x00 0x00 0x00 0x00 0x00 0x00 0x00 0x00 0x00 0x00 0x00 0x00 0x00 0x00 0x00 0x00 0x00 0x00 0x00 0x00 0x00 0x00 0x00 0x00 0x00 0x00 0x00 0x00 0x00 0x00 0x00 0x00 0x00 0x00 0x8020221f 0x220f40f 0x12 0x64000 0x310640 0x6400030 0x1900017 0xc1e0030a 0x1f13612f 0x14 0x80d 0x550 0xf3200000 0x00 0xce6 0x2b 0x00 0x00 0x1b 0x1b 0x30020000 0x8033 0x00 0x11 0x3000 0x2000000 0x2000101 0x07 0x30808 0x15c00 0x102020 0x1fff1fff 0x00 0x00 0x00 0x34 0x40 0x18000800 0x8000800 0x8000800 0x8000800 0x400080 0x8801004 0x20 0x00 0x00 0x00 0x00 0x00 0x00 0xefff2210 0x00 0x00 0xdcdcdcdc 0xa0a0a0a 0xa0a0a0a 0xa0a0a0a 0x1186190 0x01 0x1f 0x45 0x35 0x47 0x88161414 0x3d 0x6000c 0x9080 0x7070404 0x40320 0x513801f 0x1f101100 0x14 0x103200 0x1124000 0x1125b6a 0xf081000 0x105800 0x1110fc00 0xf085300 0x105800 0x1114fc00 0x7004300 0x103200 0x55553c5a 0xc8161414>;
				nvidia,emc-shadow-regs-rdwr-train = <0x66 0x1c0 0xe0 0x00 0x00 0x47 0x20 0x29 0x21 0x0c 0x2d 0x00 0x04 0x20 0x20 0x20 0x13 0x17 0x16 0x06 0x0e 0x0c 0x0a 0x0e 0x08 0x0d 0x24 0x08 0x1000001c 0x10000002 0x14 0x8803f1f1 0x1c 0x1f 0x0d 0x6000c 0x33 0x3b 0x3d 0x39 0x3b 0x5e9 0x00 0x17a 0x10 0x10 0x03 0x03 0x03 0x38 0x0e 0x02 0x31 0x1cc 0x1cc 0x0d 0x18 0x0c 0x40 0x25 0x04 0x14 0xc803f1f1 0x1860 0x00 0x9960a00d 0x3bff 0xc00001bb 0x8000 0x55 0x00 0x00 0x00 0x00 0x00 0x00 0x880b6666 0x8000e 0x11000c 0x1c001c 0x1c001c 0x1c001c 0x1c001c 0x07 0x90002 0x1c001c 0x1c001c 0x1c001c 0x1c001c 0x07 0x90002 0xe000e 0x80008 0xc000c 0x110011 0x0e 0x00 0x00 0x00 0x00 0x00 0x00 0x00 0x00 0x00 0x00 0x00 0x00 0x00 0x00 0x00 0x00 0x00 0x00 0x00 0x00 0x00 0x00 0x00 0x00 0x00 0x00 0x00 0x00 0x00 0x00 0x00 0x00 0x00 0x00 0x00 0x00 0x00 0x00 0x00 0x00 0x8020221f 0x220f40f 0x12 0x64000 0x310640 0x6400030 0x1900017 0xc1e0030a 0x1f13612f 0x14 0x80d 0x550 0xf3200000 0x00 0xce6 0x2b 0x00 0x00 0x1b 0x1b 0x20000 0x33 0x00 0x11 0x3000 0x2000000 0x2000101 0x07 0x30808 0x15c00 0x102020 0x1fff1fff 0x00 0x00 0x00 0x34 0x40 0x18000800 0x8000800 0x8000800 0x8000800 0x400080 0x8801004 0x20 0x00 0x00 0x00 0x00 0x00 0x00 0xefff2210 0x00 0x00 0xdcdcdcdc 0xa0a0a0a 0xa0a0a0a 0xa0a0a0a 0x1186190 0x01 0x00 0x3b 0x2b 0x3d 0x88161414 0x33 0x6000c 0xb080 0x7070404 0x40320 0x513801f 0x1f101100 0x14 0x103200 0x1124000 0x1125b6a 0xf081000 0x105800 0x1110fc00 0xf085300 0x105800 0x1114fc00 0x7004300 0x103200 0x55553c5a 0xc8161414>;
				nvidia,emc-trim-regs = <0x200020 0x200020 0x200020 0x200020 0x200020 0x200020 0x200020 0x200020 0x00 0x00 0x00 0x00 0x00 0x00 0x00 0x00 0x00 0x00 0x00 0x00 0x00 0x00 0x00 0x00 0x00 0x00 0x00 0x00 0x00 0x00 0x00 0x00 0x00 0x00 0x00 0x00 0x00 0x00 0x00 0x00 0x00 0x00 0x00 0x00 0x00 0x00 0x00 0x00 0x00 0x00 0x00 0x00 0x00 0x00 0x00 0x00 0x11111111 0x11111111 0x11111111 0x11111111 0x2b0022 0x2b0026 0x260025 0x260026 0x8000e 0x11000c 0x2b0022 0x2b0026 0x260025 0x260026 0x00 0x00 0x00 0x00 0x00 0x00 0x00 0x00 0x00 0x00 0x00 0x00 0x00 0x00 0x00 0x00 0x00 0x00 0x00 0x00 0x00 0x00 0x00 0x00 0x00 0x00 0x00 0x00 0x00 0x00 0x00 0x00 0x00 0x00 0x00 0x00 0x00 0x00 0x00 0x00 0x00 0x00 0x00 0x00 0x00 0x00 0x00 0x00 0x00 0x00 0x00 0x00 0x00 0x00 0x00 0x00 0x00 0x00 0x00 0x00 0x00 0x00 0x00 0x00 0x00 0x00 0x00 0x00>;
				nvidia,emc-trim-regs-per-ch = <0x00 0x00 0x00 0x00 0x00 0x00 0x00 0x00 0x00 0x00>;
				nvidia,emc-vref-regs = <0x00 0x00 0x00 0x00>;
				nvidia,emc-dram-timing-regs = <0x13 0x104 0x118 0x07 0x20>;
				nvidia,emc-training-mod-regs = <0x00 0x00 0x00 0x00 0x00 0x00 0x00 0x00 0x00 0x00 0x00 0x00 0x00 0x00 0x00 0x00 0x00 0x00 0x00 0x00>;
				nvidia,emc-save-restore-mod-regs = <0x00 0x00 0x00 0x00 0x00 0x00 0x00 0x00 0x04 0x04 0x04 0x04>;
				nvidia,emc-burst-mc-regs = <0x0c 0x80000080 0xa1020 0x80001028 0x06 0x07 0x19 0x10 0x0f 0x04 0x03 0x0e 0x01 0x01 0x0c 0x08 0x0a 0x37 0x5060000 0xe090c 0x726c241a 0x70000f0f 0x00 0x1f0000 0x80001a 0x80001a 0x80001a 0x80001a 0x80001a 0x80001a 0x80001a 0x80001a 0x80001a>;
				nvidia,emc-la-scale-regs = <0xd0 0x80001a 0x1203 0x80003d 0x800038 0x800041 0x800090 0x800005 0x800090 0x800005 0x340049 0x800080 0x800004 0x80016 0x80 0x800004 0x800019 0x800019 0x800018 0x800095 0x80001d 0x80 0x2c 0x800080>;
			};
		};

		emc-table@1 {
			nvidia,ram-code = <0x02>;

			emc-table@204000 {
				compatible = "nvidia,tegra21-emc-table";
				nvidia,revision = <0x07>;
				nvidia,dvfs-version = "12_204000_12_V9.8.7_V1.6";
				clock-frequency = <0x31ce0>;
				nvidia,emc-min-mv = <0x320>;
				nvidia,gk20a-min-mv = <0x44c>;
				nvidia,source = "pllp_out0";
				nvidia,src-sel-reg = <0x40188002>;
				nvidia,needs-training = <0x00>;
				nvidia,training_pattern = <0x00>;
				nvidia,trained = <0x00>;
				nvidia,periodic_training = <0x00>;
				nvidia,trained_dram_clktree_c0d0u0 = <0x00>;
				nvidia,trained_dram_clktree_c0d0u1 = <0x00>;
				nvidia,trained_dram_clktree_c0d1u0 = <0x00>;
				nvidia,trained_dram_clktree_c0d1u1 = <0x00>;
				nvidia,trained_dram_clktree_c1d0u0 = <0x00>;
				nvidia,trained_dram_clktree_c1d0u1 = <0x00>;
				nvidia,trained_dram_clktree_c1d1u0 = <0x00>;
				nvidia,trained_dram_clktree_c1d1u1 = <0x00>;
				nvidia,current_dram_clktree_c0d0u0 = <0x00>;
				nvidia,current_dram_clktree_c0d0u1 = <0x00>;
				nvidia,current_dram_clktree_c0d1u0 = <0x00>;
				nvidia,current_dram_clktree_c0d1u1 = <0x00>;
				nvidia,current_dram_clktree_c1d0u0 = <0x00>;
				nvidia,current_dram_clktree_c1d0u1 = <0x00>;
				nvidia,current_dram_clktree_c1d1u0 = <0x00>;
				nvidia,current_dram_clktree_c1d1u1 = <0x00>;
				nvidia,run_clocks = <0x0d>;
				nvidia,tree_margin = <0x01>;
				nvidia,burst-regs-num = <0xdd>;
				nvidia,burst-regs-per-ch-num = <0x08>;
				nvidia,trim-regs-num = <0x8a>;
				nvidia,trim-regs-per-ch-num = <0x0a>;
				nvidia,burst-mc-regs-num = <0x21>;
				nvidia,la-scale-regs-num = <0x18>;
				nvidia,vref-regs-num = <0x04>;
				nvidia,training-mod-regs-num = <0x14>;
				nvidia,dram-timing-regs-num = <0x05>;
				nvidia,min-mrs-wait = <0x16>;
				nvidia,emc-mrw = <0x88010004>;
				nvidia,emc-mrw2 = <0x88020000>;
				nvidia,emc-mrw3 = <0x880d0000>;
				nvidia,emc-mrw4 = <0xc0000000>;
				nvidia,emc-mrw9 = <0x8c0e7272>;
				nvidia,emc-mrs = <0x00>;
				nvidia,emc-emrs = <0x00>;
				nvidia,emc-emrs2 = <0x00>;
				nvidia,emc-auto-cal-config = <0xa01a51d8>;
				nvidia,emc-auto-cal-config2 = <0x5500000>;
				nvidia,emc-auto-cal-config3 = <0x770000>;
				nvidia,emc-auto-cal-config4 = <0x770000>;
				nvidia,emc-auto-cal-config5 = <0x770000>;
				nvidia,emc-auto-cal-config6 = <0x770000>;
				nvidia,emc-auto-cal-config7 = <0x770000>;
				nvidia,emc-auto-cal-config8 = <0x770000>;
				nvidia,emc-cfg-2 = <0x110805>;
				nvidia,emc-sel-dpd-ctrl = <0x40008>;
				nvidia,emc-fdpd-ctrl-cmd-no-ramp = <0x01>;
				nvidia,dll-clk-src = <0x40188002>;
				nvidia,clk-out-enb-x-0-clk-enb-emc-dll = <0x01>;
				nvidia,emc-clock-latency-change = <0xd5c>;
				nvidia,ptfv = <0x00 0x00 0x00 0x00 0x00 0x00 0x00 0x00 0x0a 0x0a 0x0a 0x01>;
				nvidia,emc-registers = <0x0d 0x3a 0x1d 0x00 0x00 0x09 0x04 0x0d 0x0d 0x08 0x0b 0x00 0x04 0x20 0x06 0x06 0x06 0x03 0x00 0x06 0x04 0x02 0x00 0x04 0x08 0x0d 0x06 0x05 0x00 0x00 0x03 0x88037171 0x0c 0x01 0x80000000 0x10000 0x12 0x14 0x16 0x12 0x14 0x304 0x00 0xc1 0x08 0x08 0x03 0x03 0x03 0x14 0x05 0x02 0x0d 0x3b 0x3b 0x05 0x05 0x04 0x09 0x05 0x04 0x09 0xc8037171 0x31c 0x00 0x9160a00d 0x3bbf 0x2c00a0 0x8000 0xbe 0xfff0fff 0xfff0fff 0x00 0x00 0x00 0x00 0x880b0000 0xe0017 0x1c0014 0x450031 0x3f002b 0x3d0028 0x3d0031 0x0b 0x100004 0x450031 0x3f002b 0x3d0028 0x3d0031 0x0b 0x100004 0x170017 0xe000e 0x140014 0x1c001c 0x17 0x00 0x00 0x00 0x00 0x00 0x00 0x00 0x00 0x00 0x00 0x00 0x00 0x00 0x00 0x00 0x00 0x00 0x00 0x00 0x00 0x00 0x00 0x00 0x00 0x00 0x00 0x00 0x00 0x00 0x00 0x00 0x00 0x00 0x00 0x00 0x00 0x00 0x00 0x00 0x00 0x8020221f 0x220f40f 0x12 0x64000 0x900cc 0xcc0016 0x33000a 0xc1e00303 0x1f13412f 0x10014 0x804 0x550 0xf3200000 0xfff0fff 0x713 0x0a 0x00 0x00 0x1b 0x1b 0x20000 0x50037 0x00 0x210 0x3000 0xa000000 0x2000111 0x08 0x30808 0x15c00 0x101010 0x1600 0x00 0x00 0x00 0x34 0x40 0x18000800 0x8000800 0x8000800 0x8000800 0x400080 0x8801004 0x20 0x00 0x00 0x00 0x00 0x00 0x00 0xefffefff 0xc0c0c0c0 0xc0c0c0c0 0xdcdcdcdc 0xa0a0a0a 0xa0a0a0a 0xa0a0a0a 0x1186033 0x00 0x00 0x14 0x0a 0x16 0x88161414 0x12 0x10000 0x9080 0x7070404 0x40065 0x513801f 0x1f101100 0x14 0x107240 0x1124000 0x1125b6a 0xf081000 0x105800 0x1110fc00 0xf081300 0x105800 0x1114fc00 0x7000300 0x107240 0x55553c5a 0xc8161414>;
				nvidia,emc-burst-regs-per-ch = <0x880c7272 0x880c7272 0xc80c7272 0xc80c7272 0x8c0e7272 0x8c0e7272 0x4c0e7272 0x4c0e7272>;
				nvidia,emc-shadow-regs-ca-train = <0x0d 0x3a 0x1d 0x00 0x00 0x09 0x04 0x0d 0x0d 0x08 0x0b 0x00 0x04 0x20 0x06 0x06 0x06 0x03 0x00 0x06 0x04 0x02 0x00 0x04 0x08 0x0d 0x06 0x05 0x00 0x00 0x03 0x88037171 0x0c 0x01 0x80000000 0x10000 0x12 0x14 0x16 0x12 0x14 0x304 0x00 0xc1 0x08 0x08 0x03 0x03 0x03 0x14 0x05 0x02 0x0d 0x3b 0x3b 0x05 0x05 0x04 0x09 0x05 0x04 0x09 0xc8037171 0x31c 0x00 0x9960a00d 0x3bbf 0x2c00a0 0x8000 0x55 0xfff0fff 0xfff0fff 0x00 0x00 0x00 0x00 0x880b0000 0xe0017 0x1c0014 0x450031 0x3f002b 0x3d0028 0x3d0031 0x0b 0x100004 0x450031 0x3f002b 0x3d0028 0x3d0031 0x0b 0x100004 0x170017 0xe000e 0x140014 0x1c001c 0x17 0x00 0x00 0x00 0x00 0x00 0x00 0x00 0x00 0x00 0x00 0x00 0x00 0x00 0x00 0x00 0x00 0x00 0x00 0x00 0x00 0x00 0x00 0x00 0x00 0x00 0x00 0x00 0x00 0x00 0x00 0x00 0x00 0x00 0x00 0x00 0x00 0x00 0x00 0x00 0x00 0x8020221f 0x220f40f 0x12 0x64000 0x900cc 0xcc0016 0x33000a 0xc1e00303 0x1f13412f 0x10014 0x804 0x550 0xf3200000 0xfff0fff 0x713 0x0a 0x00 0x00 0x1b 0x1b 0x20000 0x5058033 0x5050000 0x200 0x3000 0xa000000 0x2000111 0x08 0x30808 0x15c00 0x101010 0x1600 0x00 0x00 0x00 0x34 0x40 0x18000800 0x8000800 0x8000800 0x8000800 0x400080 0x8801004 0x20 0x00 0x00 0x00 0x00 0x00 0x00 0xefffefff 0xc0c0c0c0 0xc0c0c0c0 0xdcdcdcdc 0xa0a0a0a 0xa0a0a0a 0xa0a0a0a 0x1186033 0x01 0x1f 0x18 0x08 0x1a 0x88161414 0x10 0x10000 0x9080 0x7070404 0x40065 0x513801f 0x1f101100 0x14 0x107240 0x1124000 0x1125b6a 0xf081000 0x105800 0x1110fc00 0xf081300 0x105800 0x1114fc00 0x7000300 0x107240 0x55553c5a 0xc8161414>;
				nvidia,emc-shadow-regs-quse-train = <0x0d 0x3a 0x1d 0x00 0x00 0x09 0x04 0x0c 0x0d 0x08 0x0b 0x00 0x04 0x20 0x06 0x06 0x06 0x0c 0x00 0x06 0x04 0x02 0x00 0x04 0x08 0x0d 0x03 0x02 0x10000000 0x00 0x03 0x88037171 0x0b 0x01 0x80000000 0x40000 0x12 0x14 0x16 0x12 0x14 0x304 0x00 0xc1 0x08 0x08 0x03 0x03 0x03 0x14 0x05 0x02 0x0d 0x3b 0x3b 0x05 0x05 0x04 0x09 0x05 0x04 0x09 0xc8037171 0x31c 0x00 0x9160400d 0x3bbf 0x2c00a0 0x8000 0xbe 0xfff0fff 0xfff0fff 0x00 0x00 0x00 0x00 0x880b0000 0xe0017 0x1c0014 0x450031 0x3f002b 0x3d0028 0x3d0031 0x0b 0x100004 0x450031 0x3f002b 0x3d0028 0x3d0031 0x0b 0x100004 0x170017 0xe000e 0x140014 0x1c001c 0x17 0x00 0x00 0x00 0x00 0x00 0x00 0x00 0x00 0x00 0x00 0x00 0x00 0x00 0x00 0x00 0x00 0x00 0x00 0x00 0x00 0x00 0x00 0x00 0x00 0x00 0x00 0x00 0x00 0x00 0x00 0x00 0x00 0x00 0x00 0x00 0x00 0x00 0x00 0x00 0x00 0x8020221f 0x220f40f 0x12 0x64000 0x900cc 0xcc0016 0x33000a 0xc1e00303 0x1f13412f 0x10014 0x804 0x550 0xf3200000 0xfff0fff 0x713 0x0a 0x00 0x00 0x1b 0x1b 0x30020000 0x58037 0x00 0x210 0x3000 0xa000000 0x2000111 0x08 0x30808 0x15c00 0x101010 0x1600 0x00 0x00 0x00 0x34 0x40 0x18000800 0x8000800 0x8000800 0x8000800 0x400080 0x8801004 0x20 0x00 0x00 0x00 0x00 0x00 0x00 0xefffefff 0xc0c0c0c0 0xc0c0c0c0 0xdcdcdcdc 0xa0a0a0a 0xa0a0a0a 0xa0a0a0a 0x1186033 0x01 0x1f 0x1e 0x14 0x20 0x88161414 0x1c 0x40000 0x9080 0x7070404 0x40065 0x513801f 0x1f101100 0x14 0x107240 0x1124000 0x1125b6a 0xf081000 0x105800 0x1110fc00 0xf081300 0x105800 0x1114fc00 0x7000300 0x107240 0x55553c5a 0xc8161414>;
				nvidia,emc-shadow-regs-rdwr-train = <0x0d 0x3a 0x1d 0x00 0x00 0x09 0x04 0x10 0x0d 0x08 0x0b 0x00 0x04 0x20 0x06 0x06 0x06 0x12 0x13 0x06 0x04 0x02 0x00 0x04 0x08 0x0d 0x06 0x05 0x10000000 0x30000002 0x03 0x88037171 0x0c 0x01 0x80000000 0x40000 0x12 0x14 0x16 0x12 0x14 0x304 0x00 0xc1 0x08 0x08 0x03 0x03 0x03 0x14 0x05 0x02 0x0d 0x3b 0x3b 0x05 0x05 0x04 0x09 0x05 0x04 0x09 0xc8037171 0x31c 0x00 0x9160a00d 0x3bbf 0x2c00a0 0x8000 0xbe 0xfff0fff 0xfff0fff 0x00 0x00 0x00 0x00 0x880b0000 0xe0017 0x1c0014 0x450031 0x3f002b 0x3d0028 0x3d0031 0x0b 0x100004 0x450031 0x3f002b 0x3d0028 0x3d0031 0x0b 0x100004 0x170017 0xe000e 0x140014 0x1c001c 0x17 0x00 0x00 0x00 0x00 0x00 0x00 0x00 0x00 0x00 0x00 0x00 0x00 0x00 0x00 0x00 0x00 0x00 0x00 0x00 0x00 0x00 0x00 0x00 0x00 0x00 0x00 0x00 0x00 0x00 0x00 0x00 0x00 0x00 0x00 0x00 0x00 0x00 0x00 0x00 0x00 0x8020221f 0x220f40f 0x12 0x64000 0x900cc 0xcc0016 0x33000a 0xc1e00303 0x1f13412f 0x10014 0x804 0x550 0xf3200000 0xfff0fff 0x713 0x0a 0x00 0x00 0x1b 0x1b 0x20000 0x50037 0x00 0x210 0x3000 0xa000000 0x2000111 0x08 0x30808 0x15c00 0x101010 0x1600 0x00 0x00 0x00 0x34 0x40 0x18000800 0x8000800 0x8000800 0x8000800 0x400080 0x8801004 0x20 0x00 0x00 0x00 0x00 0x00 0x00 0xefffefff 0xc0c0c0c0 0xc0c0c0c0 0xdcdcdcdc 0xa0a0a0a 0xa0a0a0a 0xa0a0a0a 0x1186033 0x01 0x00 0x14 0x0a 0x16 0x88161414 0x12 0x40000 0xb080 0x7070404 0x40065 0x513801f 0x1f101100 0x14 0x107240 0x1124000 0x1125b6a 0xf081000 0x105800 0x1110fc00 0xf081300 0x105800 0x1114fc00 0x7000300 0x107240 0x55553c5a 0xc8161414>;
				nvidia,emc-trim-regs = <0x280028 0x280028 0x280028 0x280028 0x280028 0x280028 0x280028 0x280028 0x00 0x00 0x00 0x00 0x00 0x00 0x00 0x00 0x00 0x00 0x00 0x00 0x00 0x00 0x00 0x00 0x00 0x00 0x00 0x00 0x00 0x00 0x00 0x00 0x00 0x00 0x00 0x00 0x00 0x00 0x00 0x00 0x00 0x00 0x00 0x00 0x00 0x00 0x00 0x00 0x00 0x00 0x00 0x00 0x00 0x00 0x00 0x00 0x11111111 0x11111111 0x28282828 0x28282828 0x00 0x00 0x00 0x00 0xe0017 0x1c0014 0x00 0x00 0x00 0x00 0x00 0x00 0x00 0x00 0x00 0x00 0x00 0x00 0x00 0x00 0x00 0x00 0x00 0x00 0x00 0x00 0x00 0x00 0x00 0x00 0x00 0x00 0x00 0x00 0x00 0x00 0x00 0x00 0x00 0x00 0x00 0x00 0x00 0x00 0x00 0x00 0x00 0x00 0x00 0x00 0x00 0x00 0x00 0x00 0x00 0x00 0x00 0x00 0x00 0x00 0x00 0x00 0x00 0x00 0x00 0x00 0x00 0x00 0x00 0x00 0x00 0x00 0x00 0x00 0x00 0x00 0x00 0x00>;
				nvidia,emc-trim-regs-per-ch = <0x00 0x00 0x249249 0x249249 0x249249 0x249249 0x00 0x00 0x00 0x00>;
				nvidia,emc-vref-regs = <0x00 0x00 0x00 0x00>;
				nvidia,emc-dram-timing-regs = <0x12 0x104 0x118 0x18 0x06>;
				nvidia,emc-training-mod-regs = <0x00 0x00 0x00 0x00 0x00 0x00 0x00 0x00 0x00 0x00 0x00 0x00 0x00 0x00 0x00 0x00 0x00 0x00 0x00 0x00>;
				nvidia,emc-save-restore-mod-regs = <0x00 0x00 0x00 0x00 0x00 0x00 0x00 0x00 0x00 0x00 0x00 0x00>;
				nvidia,emc-burst-mc-regs = <0x8000001 0x8000004c 0xa1020 0x80001028 0x01 0x00 0x03 0x01 0x02 0x01 0x02 0x05 0x01 0x01 0x05 0x08 0x05 0x07 0x2020000 0x30201 0x72a30504 0x70000f0f 0x00 0x1f0000 0x80001a 0x80001a 0x80001a 0x80001a 0x80001a 0x80001a 0x80001a 0x80001a 0x80001a>;
				nvidia,emc-la-scale-regs = <0x1b 0x80001a 0x24c 0xff00b2 0xff00da 0xff009d 0xff00ff 0xff000c 0xff00ff 0xff000c 0x7f0049 0xff0080 0xff0004 0x800ad 0xff 0xff0004 0xff00c6 0xff00c6 0xff006d 0xff00ff 0xff00e2 0xff 0x80 0xff00ff>;
			};

			emc-table@1600000 {
				compatible = "nvidia,tegra21-emc-table";
				nvidia,revision = <0x07>;
				nvidia,dvfs-version = "12_1600000_12_V9.8.7_V1.6";
				clock-frequency = <0x186a00>;
				nvidia,emc-min-mv = <0x377>;
				nvidia,gk20a-min-mv = <0x44c>;
				nvidia,source = "pllm_ud";
				nvidia,src-sel-reg = <0x80188000>;
				nvidia,needs-training = <0x2f0>;
				nvidia,training_pattern = <0x00>;
				nvidia,trained = <0x00>;
				nvidia,periodic_training = <0x01>;
				nvidia,trained_dram_clktree_c0d0u0 = <0x00>;
				nvidia,trained_dram_clktree_c0d0u1 = <0x00>;
				nvidia,trained_dram_clktree_c0d1u0 = <0x00>;
				nvidia,trained_dram_clktree_c0d1u1 = <0x00>;
				nvidia,trained_dram_clktree_c1d0u0 = <0x00>;
				nvidia,trained_dram_clktree_c1d0u1 = <0x00>;
				nvidia,trained_dram_clktree_c1d1u0 = <0x00>;
				nvidia,trained_dram_clktree_c1d1u1 = <0x00>;
				nvidia,current_dram_clktree_c0d0u0 = <0x00>;
				nvidia,current_dram_clktree_c0d0u1 = <0x00>;
				nvidia,current_dram_clktree_c0d1u0 = <0x00>;
				nvidia,current_dram_clktree_c0d1u1 = <0x00>;
				nvidia,current_dram_clktree_c1d0u0 = <0x00>;
				nvidia,current_dram_clktree_c1d0u1 = <0x00>;
				nvidia,current_dram_clktree_c1d1u0 = <0x00>;
				nvidia,current_dram_clktree_c1d1u1 = <0x00>;
				nvidia,run_clocks = <0x40>;
				nvidia,tree_margin = <0x01>;
				nvidia,burst-regs-num = <0xdd>;
				nvidia,burst-regs-per-ch-num = <0x08>;
				nvidia,trim-regs-num = <0x8a>;
				nvidia,trim-regs-per-ch-num = <0x0a>;
				nvidia,burst-mc-regs-num = <0x21>;
				nvidia,la-scale-regs-num = <0x18>;
				nvidia,vref-regs-num = <0x04>;
				nvidia,training-mod-regs-num = <0x14>;
				nvidia,dram-timing-regs-num = <0x05>;
				nvidia,min-mrs-wait = <0x30>;
				nvidia,emc-mrw = <0x88010054>;
				nvidia,emc-mrw2 = <0x8802002d>;
				nvidia,emc-mrw3 = <0x880d0000>;
				nvidia,emc-mrw4 = <0xc0000000>;
				nvidia,emc-mrw9 = <0x8c0e4848>;
				nvidia,emc-mrs = <0x00>;
				nvidia,emc-emrs = <0x00>;
				nvidia,emc-emrs2 = <0x00>;
				nvidia,emc-auto-cal-config = <0xa01a51d8>;
				nvidia,emc-auto-cal-config2 = <0x5500000>;
				nvidia,emc-auto-cal-config3 = <0x770000>;
				nvidia,emc-auto-cal-config4 = <0x770000>;
				nvidia,emc-auto-cal-config5 = <0x770000>;
				nvidia,emc-auto-cal-config6 = <0x770000>;
				nvidia,emc-auto-cal-config7 = <0x770000>;
				nvidia,emc-auto-cal-config8 = <0x770000>;
				nvidia,emc-cfg-2 = <0x110835>;
				nvidia,emc-sel-dpd-ctrl = <0x40000>;
				nvidia,emc-fdpd-ctrl-cmd-no-ramp = <0x01>;
				nvidia,dll-clk-src = <0x80188000>;
				nvidia,clk-out-enb-x-0-clk-enb-emc-dll = <0x00>;
				nvidia,emc-clock-latency-change = <0x49c>;
				nvidia,ptfv = <0x00 0x00 0x00 0x00 0x00 0x00 0x00 0x00 0x0a 0x0a 0x0a 0x01>;
				nvidia,emc-registers = <0x60 0x1c0 0xe0 0x00 0x00 0x44 0x1d 0x2b 0x21 0x0c 0x2d 0x00 0x04 0x20 0x1d 0x1d 0x10 0x17 0x16 0x06 0x0e 0x0c 0x0a 0x0e 0x08 0x0d 0x24 0x08 0x1000001c 0x10000002 0x14 0x8803f1f1 0x1c 0x01 0x80000000 0x6000c 0x33 0x3b 0x3d 0x39 0x3b 0x1820 0x00 0x608 0x10 0x10 0x03 0x03 0x03 0x38 0x0e 0x02 0x2e 0x1cc 0x1cc 0x0d 0x18 0x0c 0x40 0x22 0x04 0x14 0xc803f1f1 0x1860 0x00 0x9960a00d 0x3bff 0xc00001bb 0x8000 0x55 0x00 0x00 0x00 0x00 0x00 0x00 0x880b6666 0x8000e 0x11000c 0x1c001c 0x1c001c 0x1c001c 0x1c001c 0x07 0x90002 0x1c001c 0x1c001c 0x1c001c 0x1c001c 0x07 0x90002 0xe000e 0x80008 0xc000c 0x110011 0x0e 0x00 0x00 0x00 0x00 0x00 0x00 0x00 0x00 0x00 0x00 0x00 0x00 0x00 0x00 0x00 0x00 0x00 0x00 0x00 0x00 0x00 0x00 0x00 0x00 0x00 0x00 0x00 0x00 0x00 0x00 0x00 0x00 0x00 0x00 0x00 0x00 0x00 0x00 0x00 0x00 0x8020221f 0x220f40f 0x12 0x64000 0x310640 0x6400030 0x1900017 0xc1e0030a 0x1f13612f 0x14 0x80d 0x550 0xf3200000 0x00 0x308c 0x2b 0x00 0x00 0x1b 0x1b 0x20000 0x33 0x00 0x211 0x3000 0x2000000 0x2000101 0x07 0x30808 0x15c00 0x102020 0x1fff1fff 0x00 0x00 0x00 0x34 0x40 0x18000800 0x8000800 0x8000800 0x8000800 0x400080 0x8801004 0x20 0x00 0x00 0x00 0x00 0x00 0x00 0xefff2210 0x00 0x00 0xdcdcdcdc 0xa0a0a0a 0xa0a0a0a 0xa0a0a0a 0x1186190 0x00 0x00 0x3b 0x2b 0x3d 0x88161414 0x33 0x6000c 0x9080 0x7070404 0x40320 0x513801f 0x1f101100 0x14 0x103200 0x1124000 0x1125b6a 0xf081000 0x105800 0x1110fc00 0xf085300 0x105800 0x1114fc00 0x7004300 0x103200 0x55553c5a 0xc8161414>;
				nvidia,emc-burst-regs-per-ch = <0x880c4848 0x880c4848 0xc80c4848 0xc80c4848 0x8c0e4848 0x8c0e4848 0x4c0e4848 0x4c0e4848>;
				nvidia,emc-shadow-regs-ca-train = <0x60 0x1c0 0xe0 0x00 0x00 0x44 0x1d 0x2b 0x21 0x0c 0x2d 0x00 0x04 0x20 0x1d 0x1d 0x10 0x17 0x16 0x06 0x0e 0x0c 0x0a 0x0e 0x08 0x0d 0x24 0x08 0x1000001c 0x10000002 0x14 0x8803f1f1 0x1c 0x01 0x80000000 0x6000c 0x33 0x3b 0x3d 0x39 0x3b 0x1820 0x00 0x608 0x10 0x10 0x03 0x03 0x03 0x38 0x0e 0x02 0x2e 0x1cc 0x1cc 0x0d 0x18 0x0c 0x40 0x22 0x04 0x14 0xc803f1f1 0x1860 0x00 0x9960a00d 0x3bff 0xc00001bb 0x8000 0x55 0x00 0x00 0x00 0x00 0x00 0x00 0x880b6666 0x8000e 0x11000c 0x1c001c 0x1c001c 0x1c001c 0x1c001c 0x07 0x90002 0x1c001c 0x1c001c 0x1c001c 0x1c001c 0x07 0x90002 0xe000e 0x80008 0xc000c 0x110011 0x0e 0x00 0x00 0x00 0x00 0x00 0x00 0x00 0x00 0x00 0x00 0x00 0x00 0x00 0x00 0x00 0x00 0x00 0x00 0x00 0x00 0x00 0x00 0x00 0x00 0x00 0x00 0x00 0x00 0x00 0x00 0x00 0x00 0x00 0x00 0x00 0x00 0x00 0x00 0x00 0x00 0x8020221f 0x220f40f 0x12 0x64000 0x310640 0x6400030 0x1900017 0xc1e0030a 0x1f13612f 0x14 0x80d 0x550 0xf3200000 0x00 0x308c 0x2b 0x00 0x00 0x1b 0x1b 0x20000 0x8033 0x00 0x200 0x3000 0x2000000 0x2000101 0x07 0x30808 0x15c00 0x102020 0x1fff1fff 0x00 0x00 0x00 0x34 0x40 0x18000800 0x8000800 0x8000800 0x8000800 0x400080 0x8801004 0x20 0x00 0x00 0x00 0x00 0x00 0x00 0xefff2210 0x00 0x00 0xdcdcdcdc 0xa0a0a0a 0xa0a0a0a 0xa0a0a0a 0x1186190 0x01 0x1f 0x41 0x2b 0x43 0x88161414 0x33 0x6000c 0x9080 0x7070404 0x40320 0x513801f 0x1f101100 0x14 0x103200 0x1124000 0x1125b6a 0xf081000 0x105800 0x1110fc00 0xf085300 0x105800 0x1114fc00 0x7004300 0x103200 0x55553c5a 0xc8161414>;
				nvidia,emc-shadow-regs-quse-train = <0x60 0x1c0 0xe0 0x00 0x00 0x44 0x1d 0x2a 0x21 0x0c 0x2d 0x00 0x04 0x20 0x1d 0x1d 0x10 0x11 0x16 0x06 0x0e 0x0c 0x0a 0x0e 0x08 0x0d 0x21 0x02 0x1000001c 0x10000002 0x14 0x8803f1f1 0x1b 0x01 0x80000000 0x6000c 0x33 0x3b 0x3d 0x39 0x3b 0x1820 0x00 0x608 0x10 0x10 0x03 0x03 0x03 0x38 0x0e 0x02 0x2e 0x1cc 0x1cc 0x0d 0x18 0x0c 0x40 0x22 0x04 0x14 0xc803f1f1 0x1860 0x00 0x9960400d 0x3bff 0xc00001bb 0x8000 0x55 0x00 0x00 0x00 0x00 0x00 0x00 0x880b6666 0x8000e 0x11000c 0x1c001c 0x1c001c 0x1c001c 0x1c001c 0x07 0x90002 0x1c001c 0x1c001c 0x1c001c 0x1c001c 0x07 0x90002 0xe000e 0x80008 0xc000c 0x110011 0x0e 0x00 0x00 0x00 0x00 0x00 0x00 0x00 0x00 0x00 0x00 0x00 0x00 0x00 0x00 0x00 0x00 0x00 0x00 0x00 0x00 0x00 0x00 0x00 0x00 0x00 0x00 0x00 0x00 0x00 0x00 0x00 0x00 0x00 0x00 0x00 0x00 0x00 0x00 0x00 0x00 0x8020221f 0x220f40f 0x12 0x64000 0x310640 0x6400030 0x1900017 0xc1e0030a 0x1f13612f 0x14 0x80d 0x550 0xf3200000 0x00 0x308c 0x2b 0x00 0x00 0x1b 0x1b 0x30020000 0x8033 0x00 0x211 0x3000 0x2000000 0x2000101 0x07 0x30808 0x15c00 0x102020 0x1fff1fff 0x00 0x00 0x00 0x34 0x40 0x18000800 0x8000800 0x8000800 0x8000800 0x400080 0x8801004 0x20 0x00 0x00 0x00 0x00 0x00 0x00 0xefff2210 0x00 0x00 0xdcdcdcdc 0xa0a0a0a 0xa0a0a0a 0xa0a0a0a 0x1186190 0x01 0x1f 0x45 0x35 0x47 0x88161414 0x3d 0x6000c 0x9080 0x7070404 0x40320 0x513801f 0x1f101100 0x14 0x103200 0x1124000 0x1125b6a 0xf081000 0x105800 0x1110fc00 0xf085300 0x105800 0x1114fc00 0x7004300 0x103200 0x55553c5a 0xc8161414>;
				nvidia,emc-shadow-regs-rdwr-train = <0x60 0x1c0 0xe0 0x00 0x00 0x44 0x1d 0x2b 0x21 0x0c 0x2d 0x00 0x04 0x20 0x1d 0x1d 0x10 0x17 0x16 0x06 0x0e 0x0c 0x0a 0x0e 0x08 0x0d 0x24 0x08 0x1000001c 0x10000002 0x14 0x8803f1f1 0x1c 0x01 0x80000000 0x6000c 0x33 0x3b 0x3d 0x39 0x3b 0x1820 0x00 0x608 0x10 0x10 0x03 0x03 0x03 0x38 0x0e 0x02 0x2e 0x1cc 0x1cc 0x0d 0x18 0x0c 0x40 0x22 0x04 0x14 0xc803f1f1 0x1860 0x00 0x9960a00d 0x3bff 0xc00001bb 0x8000 0x55 0x00 0x00 0x00 0x00 0x00 0x00 0x880b6666 0x8000e 0x11000c 0x1c001c 0x1c001c 0x1c001c 0x1c001c 0x07 0x90002 0x1c001c 0x1c001c 0x1c001c 0x1c001c 0x07 0x90002 0xe000e 0x80008 0xc000c 0x110011 0x0e 0x00 0x00 0x00 0x00 0x00 0x00 0x00 0x00 0x00 0x00 0x00 0x00 0x00 0x00 0x00 0x00 0x00 0x00 0x00 0x00 0x00 0x00 0x00 0x00 0x00 0x00 0x00 0x00 0x00 0x00 0x00 0x00 0x00 0x00 0x00 0x00 0x00 0x00 0x00 0x00 0x8020221f 0x220f40f 0x12 0x64000 0x310640 0x6400030 0x1900017 0xc1e0030a 0x1f13612f 0x14 0x80d 0x550 0xf3200000 0x00 0x308c 0x2b 0x00 0x00 0x1b 0x1b 0x20000 0x33 0x00 0x211 0x3000 0x2000000 0x2000101 0x07 0x30808 0x15c00 0x102020 0x1fff1fff 0x00 0x00 0x00 0x34 0x40 0x18000800 0x8000800 0x8000800 0x8000800 0x400080 0x8801004 0x20 0x00 0x00 0x00 0x00 0x00 0x00 0xefff2210 0x00 0x00 0xdcdcdcdc 0xa0a0a0a 0xa0a0a0a 0xa0a0a0a 0x1186190 0x01 0x00 0x3b 0x2b 0x3d 0x88161414 0x33 0x6000c 0xb080 0x7070404 0x40320 0x513801f 0x1f101100 0x14 0x103200 0x1124000 0x1125b6a 0xf081000 0x105800 0x1110fc00 0xf085300 0x105800 0x1114fc00 0x7004300 0x103200 0x55553c5a 0xc8161414>;
				nvidia,emc-trim-regs = <0x200020 0x200020 0x200020 0x200020 0x200020 0x200020 0x200020 0x200020 0x00 0x00 0x00 0x00 0x00 0x00 0x00 0x00 0x00 0x00 0x00 0x00 0x00 0x00 0x00 0x00 0x00 0x00 0x00 0x00 0x00 0x00 0x00 0x00 0x00 0x00 0x00 0x00 0x00 0x00 0x00 0x00 0x00 0x00 0x00 0x00 0x00 0x00 0x00 0x00 0x00 0x00 0x00 0x00 0x00 0x00 0x00 0x00 0x17171717 0x17171717 0x11111111 0x11111111 0x2b0022 0x2b0026 0x260025 0x260026 0x8000e 0x11000c 0x2b0022 0x2b0026 0x260025 0x260026 0x00 0x00 0x00 0x00 0x00 0x00 0x00 0x00 0x00 0x00 0x00 0x00 0x00 0x00 0x00 0x00 0x00 0x00 0x00 0x00 0x00 0x00 0x00 0x00 0x00 0x00 0x00 0x00 0x00 0x00 0x00 0x00 0x00 0x00 0x00 0x00 0x00 0x00 0x00 0x00 0x00 0x00 0x00 0x00 0x00 0x00 0x00 0x00 0x00 0x00 0x00 0x00 0x00 0x00 0x00 0x00 0x00 0x00 0x00 0x00 0x00 0x00 0x00 0x00 0x00 0x00 0x00 0x00>;
				nvidia,emc-trim-regs-per-ch = <0x00 0x00 0x00 0x00 0x00 0x00 0x00 0x00 0x00 0x00>;
				nvidia,emc-vref-regs = <0x00 0x00 0x00 0x00>;
				nvidia,emc-dram-timing-regs = <0x12 0x104 0x118 0x07 0x20>;
				nvidia,emc-training-mod-regs = <0x00 0x00 0x00 0x00 0x00 0x00 0x00 0x00 0x00 0x00 0x00 0x00 0x00 0x00 0x00 0x00 0x00 0x00 0x00 0x00>;
				nvidia,emc-save-restore-mod-regs = <0x00 0x00 0x00 0x00 0x00 0x00 0x00 0x00 0x04 0x04 0x04 0x04>;
				nvidia,emc-burst-mc-regs = <0x0c 0x80000080 0xa1020 0x80001028 0x06 0x07 0x18 0x0f 0x0f 0x03 0x03 0x0d 0x01 0x01 0x0c 0x08 0x0a 0x37 0x5060000 0xd080c 0x726c2419 0x70000f0f 0x00 0x1f0000 0x80001a 0x80001a 0x80001a 0x80001a 0x80001a 0x80001a 0x80001a 0x80001a 0x80001a>;
				nvidia,emc-la-scale-regs = <0xd0 0x80001a 0x1203 0x80003d 0x800038 0x800041 0x800090 0x800005 0x800090 0x800005 0x340049 0x800080 0x800004 0x80016 0x80 0x800004 0x800019 0x800019 0x800018 0x800095 0x80001d 0x80 0x2c 0x800080>;
			};

			emc-table-derated@204000 {
				compatible = "nvidia,tegra21-emc-table-derated";
				nvidia,revision = <0x07>;
				nvidia,dvfs-version = "12_derating_204000_12_V9.8.7_V1.6";
				clock-frequency = <0x31ce0>;
				nvidia,emc-min-mv = <0x320>;
				nvidia,gk20a-min-mv = <0x44c>;
				nvidia,source = "pllp_out0";
				nvidia,src-sel-reg = <0x40188002>;
				nvidia,needs-training = <0x00>;
				nvidia,training_pattern = <0x00>;
				nvidia,trained = <0x00>;
				nvidia,periodic_training = <0x00>;
				nvidia,trained_dram_clktree_c0d0u0 = <0x00>;
				nvidia,trained_dram_clktree_c0d0u1 = <0x00>;
				nvidia,trained_dram_clktree_c0d1u0 = <0x00>;
				nvidia,trained_dram_clktree_c0d1u1 = <0x00>;
				nvidia,trained_dram_clktree_c1d0u0 = <0x00>;
				nvidia,trained_dram_clktree_c1d0u1 = <0x00>;
				nvidia,trained_dram_clktree_c1d1u0 = <0x00>;
				nvidia,trained_dram_clktree_c1d1u1 = <0x00>;
				nvidia,current_dram_clktree_c0d0u0 = <0x00>;
				nvidia,current_dram_clktree_c0d0u1 = <0x00>;
				nvidia,current_dram_clktree_c0d1u0 = <0x00>;
				nvidia,current_dram_clktree_c0d1u1 = <0x00>;
				nvidia,current_dram_clktree_c1d0u0 = <0x00>;
				nvidia,current_dram_clktree_c1d0u1 = <0x00>;
				nvidia,current_dram_clktree_c1d1u0 = <0x00>;
				nvidia,current_dram_clktree_c1d1u1 = <0x00>;
				nvidia,run_clocks = <0x0d>;
				nvidia,tree_margin = <0x01>;
				nvidia,burst-regs-num = <0xdd>;
				nvidia,burst-regs-per-ch-num = <0x08>;
				nvidia,trim-regs-num = <0x8a>;
				nvidia,trim-regs-per-ch-num = <0x0a>;
				nvidia,burst-mc-regs-num = <0x21>;
				nvidia,la-scale-regs-num = <0x18>;
				nvidia,vref-regs-num = <0x04>;
				nvidia,training-mod-regs-num = <0x14>;
				nvidia,dram-timing-regs-num = <0x05>;
				nvidia,min-mrs-wait = <0x16>;
				nvidia,emc-mrw = <0x88010004>;
				nvidia,emc-mrw2 = <0x88020000>;
				nvidia,emc-mrw3 = <0x880d0000>;
				nvidia,emc-mrw4 = <0xc0000000>;
				nvidia,emc-mrw9 = <0x8c0e7272>;
				nvidia,emc-mrs = <0x00>;
				nvidia,emc-emrs = <0x00>;
				nvidia,emc-emrs2 = <0x00>;
				nvidia,emc-auto-cal-config = <0xa01a51d8>;
				nvidia,emc-auto-cal-config2 = <0x5500000>;
				nvidia,emc-auto-cal-config3 = <0x770000>;
				nvidia,emc-auto-cal-config4 = <0x770000>;
				nvidia,emc-auto-cal-config5 = <0x770000>;
				nvidia,emc-auto-cal-config6 = <0x770000>;
				nvidia,emc-auto-cal-config7 = <0x770000>;
				nvidia,emc-auto-cal-config8 = <0x770000>;
				nvidia,emc-cfg-2 = <0x110805>;
				nvidia,emc-sel-dpd-ctrl = <0x40008>;
				nvidia,emc-fdpd-ctrl-cmd-no-ramp = <0x01>;
				nvidia,dll-clk-src = <0x40188002>;
				nvidia,clk-out-enb-x-0-clk-enb-emc-dll = <0x01>;
				nvidia,emc-clock-latency-change = <0xd5c>;
				nvidia,ptfv = <0x00 0x00 0x00 0x00 0x00 0x00 0x00 0x00 0x0a 0x0a 0x0a 0x01>;
				nvidia,emc-registers = <0x0d 0x3a 0x1d 0x00 0x00 0x09 0x05 0x0d 0x0d 0x08 0x0b 0x00 0x04 0x20 0x06 0x06 0x06 0x03 0x00 0x06 0x04 0x02 0x00 0x04 0x08 0x0d 0x05 0x06 0x00 0x00 0x02 0x88037171 0x0d 0x01 0x80000000 0x10000 0x12 0x14 0x16 0x12 0x14 0xc1 0x00 0x30 0x08 0x08 0x03 0x03 0x03 0x14 0x05 0x02 0x0e 0x3b 0x3b 0x05 0x05 0x04 0x09 0x05 0x04 0x09 0xc8037171 0x31c 0x00 0x9160a00d 0x3bbf 0x2c00a0 0x8000 0xbe 0xfff0fff 0xfff0fff 0x00 0x00 0x00 0x00 0x880b0000 0xe0017 0x1c0014 0x450031 0x3f002b 0x3d0028 0x3d0031 0x0b 0x100004 0x450031 0x3f002b 0x3d0028 0x3d0031 0x0b 0x100004 0x170017 0xe000e 0x140014 0x1c001c 0x17 0x00 0x00 0x00 0x00 0x00 0x00 0x00 0x00 0x00 0x00 0x00 0x00 0x00 0x00 0x00 0x00 0x00 0x00 0x00 0x00 0x00 0x00 0x00 0x00 0x00 0x00 0x00 0x00 0x00 0x00 0x00 0x00 0x00 0x00 0x00 0x00 0x00 0x00 0x00 0x00 0x8020221f 0x220f40f 0x12 0x64000 0x900cc 0xcc0016 0x33000a 0xc1e00303 0x1f13412f 0x10014 0x804 0x550 0xf3200000 0xfff0fff 0x287 0x0a 0x00 0x00 0x1b 0x1b 0x20000 0x50037 0x00 0x210 0x3000 0xa000000 0x2000111 0x08 0x30808 0x15c00 0x101010 0x1600 0x00 0x00 0x00 0x34 0x40 0x18000800 0x8000800 0x8000800 0x8000800 0x400080 0x8801004 0x20 0x00 0x00 0x00 0x00 0x00 0x00 0xefffefff 0xc0c0c0c0 0xc0c0c0c0 0xdcdcdcdc 0xa0a0a0a 0xa0a0a0a 0xa0a0a0a 0x1186033 0x00 0x00 0x14 0x0a 0x16 0x88161414 0x12 0x10000 0x9080 0x7070404 0x40065 0x513801f 0x1f101100 0x14 0x107240 0x1124000 0x1125b6a 0xf081000 0x105800 0x1110fc00 0xf081300 0x105800 0x1114fc00 0x7000300 0x107240 0x55553c5a 0xc8161414>;
				nvidia,emc-burst-regs-per-ch = <0x880c7272 0x880c7272 0xc80c7272 0xc80c7272 0x8c0e7272 0x8c0e7272 0x4c0e7272 0x4c0e7272>;
				nvidia,emc-shadow-regs-ca-train = <0x0d 0x3a 0x1d 0x00 0x00 0x09 0x05 0x0d 0x0d 0x08 0x0b 0x00 0x04 0x20 0x06 0x06 0x06 0x03 0x00 0x06 0x04 0x02 0x00 0x04 0x08 0x0d 0x05 0x06 0x00 0x00 0x02 0x88037171 0x0d 0x01 0x80000000 0x10000 0x12 0x14 0x16 0x12 0x14 0xc1 0x00 0x30 0x08 0x08 0x03 0x03 0x03 0x14 0x05 0x02 0x0e 0x3b 0x3b 0x05 0x05 0x04 0x09 0x05 0x04 0x09 0xc8037171 0x31c 0x00 0x9960a00d 0x3bbf 0x2c00a0 0x8000 0x55 0xfff0fff 0xfff0fff 0x00 0x00 0x00 0x00 0x880b0000 0xe0017 0x1c0014 0x450031 0x3f002b 0x3d0028 0x3d0031 0x0b 0x100004 0x450031 0x3f002b 0x3d0028 0x3d0031 0x0b 0x100004 0x170017 0xe000e 0x140014 0x1c001c 0x17 0x00 0x00 0x00 0x00 0x00 0x00 0x00 0x00 0x00 0x00 0x00 0x00 0x00 0x00 0x00 0x00 0x00 0x00 0x00 0x00 0x00 0x00 0x00 0x00 0x00 0x00 0x00 0x00 0x00 0x00 0x00 0x00 0x00 0x00 0x00 0x00 0x00 0x00 0x00 0x00 0x8020221f 0x220f40f 0x12 0x64000 0x900cc 0xcc0016 0x33000a 0xc1e00303 0x1f13412f 0x10014 0x804 0x550 0xf3200000 0xfff0fff 0x287 0x0a 0x00 0x00 0x1b 0x1b 0x20000 0x5058033 0x5050000 0x200 0x3000 0xa000000 0x2000111 0x08 0x30808 0x15c00 0x101010 0x1600 0x00 0x00 0x00 0x34 0x40 0x18000800 0x8000800 0x8000800 0x8000800 0x400080 0x8801004 0x20 0x00 0x00 0x00 0x00 0x00 0x00 0xefffefff 0xc0c0c0c0 0xc0c0c0c0 0xdcdcdcdc 0xa0a0a0a 0xa0a0a0a 0xa0a0a0a 0x1186033 0x01 0x1f 0x18 0x08 0x1a 0x88161414 0x10 0x10000 0x9080 0x7070404 0x40065 0x513801f 0x1f101100 0x14 0x107240 0x1124000 0x1125b6a 0xf081000 0x105800 0x1110fc00 0xf081300 0x105800 0x1114fc00 0x7000300 0x107240 0x55553c5a 0xc8161414>;
				nvidia,emc-shadow-regs-quse-train = <0x0d 0x3a 0x1d 0x00 0x00 0x09 0x05 0x0c 0x0d 0x08 0x0b 0x00 0x04 0x20 0x06 0x06 0x06 0x0c 0x00 0x06 0x04 0x02 0x00 0x04 0x08 0x0d 0x03 0x02 0x10000000 0x00 0x03 0x88037171 0x0b 0x01 0x80000000 0x40000 0x12 0x14 0x16 0x12 0x14 0xc1 0x00 0x30 0x08 0x08 0x03 0x03 0x03 0x14 0x05 0x02 0x0e 0x3b 0x3b 0x05 0x05 0x04 0x09 0x05 0x04 0x09 0xc8037171 0x31c 0x00 0x9160400d 0x3bbf 0x2c00a0 0x8000 0xbe 0xfff0fff 0xfff0fff 0x00 0x00 0x00 0x00 0x880b0000 0xe0017 0x1c0014 0x450031 0x3f002b 0x3d0028 0x3d0031 0x0b 0x100004 0x450031 0x3f002b 0x3d0028 0x3d0031 0x0b 0x100004 0x170017 0xe000e 0x140014 0x1c001c 0x17 0x00 0x00 0x00 0x00 0x00 0x00 0x00 0x00 0x00 0x00 0x00 0x00 0x00 0x00 0x00 0x00 0x00 0x00 0x00 0x00 0x00 0x00 0x00 0x00 0x00 0x00 0x00 0x00 0x00 0x00 0x00 0x00 0x00 0x00 0x00 0x00 0x00 0x00 0x00 0x00 0x8020221f 0x220f40f 0x12 0x64000 0x900cc 0xcc0016 0x33000a 0xc1e00303 0x1f13412f 0x10014 0x804 0x550 0xf3200000 0xfff0fff 0x287 0x0a 0x00 0x00 0x1b 0x1b 0x30020000 0x58037 0x00 0x210 0x3000 0xa000000 0x2000111 0x08 0x30808 0x15c00 0x101010 0x1600 0x00 0x00 0x00 0x34 0x40 0x18000800 0x8000800 0x8000800 0x8000800 0x400080 0x8801004 0x20 0x00 0x00 0x00 0x00 0x00 0x00 0xefffefff 0xc0c0c0c0 0xc0c0c0c0 0xdcdcdcdc 0xa0a0a0a 0xa0a0a0a 0xa0a0a0a 0x1186033 0x01 0x1f 0x1e 0x14 0x20 0x88161414 0x1c 0x40000 0x9080 0x7070404 0x40065 0x513801f 0x1f101100 0x14 0x107240 0x1124000 0x1125b6a 0xf081000 0x105800 0x1110fc00 0xf081300 0x105800 0x1114fc00 0x7000300 0x107240 0x55553c5a 0xc8161414>;
				nvidia,emc-shadow-regs-rdwr-train = <0x0d 0x3a 0x1d 0x00 0x00 0x09 0x05 0x10 0x0d 0x08 0x0b 0x00 0x04 0x20 0x06 0x06 0x06 0x13 0x13 0x06 0x04 0x02 0x00 0x04 0x08 0x0d 0x05 0x06 0x30000000 0x30000002 0x02 0x88037171 0x0d 0x01 0x80000000 0x40000 0x12 0x14 0x16 0x12 0x14 0xc1 0x00 0x30 0x08 0x08 0x03 0x03 0x03 0x14 0x05 0x02 0x0e 0x3b 0x3b 0x05 0x05 0x04 0x09 0x05 0x04 0x09 0xc8037171 0x31c 0x00 0x9160a00d 0x3bbf 0x2c00a0 0x8000 0xbe 0xfff0fff 0xfff0fff 0x00 0x00 0x00 0x00 0x880b0000 0xe0017 0x1c0014 0x450031 0x3f002b 0x3d0028 0x3d0031 0x0b 0x100004 0x450031 0x3f002b 0x3d0028 0x3d0031 0x0b 0x100004 0x170017 0xe000e 0x140014 0x1c001c 0x17 0x00 0x00 0x00 0x00 0x00 0x00 0x00 0x00 0x00 0x00 0x00 0x00 0x00 0x00 0x00 0x00 0x00 0x00 0x00 0x00 0x00 0x00 0x00 0x00 0x00 0x00 0x00 0x00 0x00 0x00 0x00 0x00 0x00 0x00 0x00 0x00 0x00 0x00 0x00 0x00 0x8020221f 0x220f40f 0x12 0x64000 0x900cc 0xcc0016 0x33000a 0xc1e00303 0x1f13412f 0x10014 0x804 0x550 0xf3200000 0xfff0fff 0x287 0x0a 0x00 0x00 0x1b 0x1b 0x20000 0x50037 0x00 0x210 0x3000 0xa000000 0x2000111 0x08 0x30808 0x15c00 0x101010 0x1600 0x00 0x00 0x00 0x34 0x40 0x18000800 0x8000800 0x8000800 0x8000800 0x400080 0x8801004 0x20 0x00 0x00 0x00 0x00 0x00 0x00 0xefffefff 0xc0c0c0c0 0xc0c0c0c0 0xdcdcdcdc 0xa0a0a0a 0xa0a0a0a 0xa0a0a0a 0x1186033 0x01 0x00 0x14 0x0a 0x16 0x88161414 0x12 0x40000 0xb080 0x7070404 0x40065 0x513801f 0x1f101100 0x14 0x107240 0x1124000 0x1125b6a 0xf081000 0x105800 0x1110fc00 0xf081300 0x105800 0x1114fc00 0x7000300 0x107240 0x55553c5a 0xc8161414>;
				nvidia,emc-trim-regs = <0x280028 0x280028 0x280028 0x280028 0x280028 0x280028 0x280028 0x280028 0x00 0x00 0x00 0x00 0x00 0x00 0x00 0x00 0x00 0x00 0x00 0x00 0x00 0x00 0x00 0x00 0x00 0x00 0x00 0x00 0x00 0x00 0x00 0x00 0x00 0x00 0x00 0x00 0x00 0x00 0x00 0x00 0x00 0x00 0x00 0x00 0x00 0x00 0x00 0x00 0x00 0x00 0x00 0x00 0x00 0x00 0x00 0x00 0x11111111 0x11111111 0x28282828 0x28282828 0x00 0x00 0x00 0x00 0xe0017 0x1c0014 0x00 0x00 0x00 0x00 0x00 0x00 0x00 0x00 0x00 0x00 0x00 0x00 0x00 0x00 0x00 0x00 0x00 0x00 0x00 0x00 0x00 0x00 0x00 0x00 0x00 0x00 0x00 0x00 0x00 0x00 0x00 0x00 0x00 0x00 0x00 0x00 0x00 0x00 0x00 0x00 0x00 0x00 0x00 0x00 0x00 0x00 0x00 0x00 0x00 0x00 0x00 0x00 0x00 0x00 0x00 0x00 0x00 0x00 0x00 0x00 0x00 0x00 0x00 0x00 0x00 0x00 0x00 0x00 0x00 0x00 0x00 0x00>;
				nvidia,emc-trim-regs-per-ch = <0x00 0x00 0x249249 0x249249 0x249249 0x249249 0x00 0x00 0x00 0x00>;
				nvidia,emc-vref-regs = <0x00 0x00 0x00 0x00>;
				nvidia,emc-dram-timing-regs = <0x13 0x104 0x118 0x18 0x06>;
				nvidia,emc-training-mod-regs = <0x00 0x00 0x00 0x00 0x00 0x00 0x00 0x00 0x00 0x00 0x00 0x00 0x00 0x00 0x00 0x00 0x00 0x00 0x00 0x00>;
				nvidia,emc-save-restore-mod-regs = <0x00 0x00 0x00 0x00 0x00 0x00 0x00 0x00 0x00 0x00 0x00 0x00>;
				nvidia,emc-burst-mc-regs = <0x8000001 0x8000004c 0xa1020 0x80001028 0x01 0x01 0x03 0x01 0x02 0x01 0x02 0x04 0x01 0x01 0x05 0x08 0x05 0x07 0x2020000 0x30201 0x72a30504 0x70000f0f 0x00 0x1f0000 0x80001a 0x80001a 0x80001a 0x80001a 0x80001a 0x80001a 0x80001a 0x80001a 0x80001a>;
				nvidia,emc-la-scale-regs = <0x1b 0x80001a 0x24c 0xff00b2 0xff00da 0xff009d 0xff00ff 0xff000c 0xff00ff 0xff000c 0x7f0049 0xff0080 0xff0004 0x800ad 0xff 0xff0004 0xff00c6 0xff00c6 0xff006d 0xff00ff 0xff00e2 0xff 0x80 0xff00ff>;
			};

			emc-table-derated@1600000 {
				compatible = "nvidia,tegra21-emc-table-derated";
				nvidia,revision = <0x07>;
				nvidia,dvfs-version = "12_derating_1600000_12_V9.8.7_V1.6";
				clock-frequency = <0x186a00>;
				nvidia,emc-min-mv = <0x377>;
				nvidia,gk20a-min-mv = <0x44c>;
				nvidia,source = "pllm_ud";
				nvidia,src-sel-reg = <0x80188000>;
				nvidia,needs-training = <0x2f0>;
				nvidia,training_pattern = <0x00>;
				nvidia,trained = <0x00>;
				nvidia,periodic_training = <0x01>;
				nvidia,trained_dram_clktree_c0d0u0 = <0x00>;
				nvidia,trained_dram_clktree_c0d0u1 = <0x00>;
				nvidia,trained_dram_clktree_c0d1u0 = <0x00>;
				nvidia,trained_dram_clktree_c0d1u1 = <0x00>;
				nvidia,trained_dram_clktree_c1d0u0 = <0x00>;
				nvidia,trained_dram_clktree_c1d0u1 = <0x00>;
				nvidia,trained_dram_clktree_c1d1u0 = <0x00>;
				nvidia,trained_dram_clktree_c1d1u1 = <0x00>;
				nvidia,current_dram_clktree_c0d0u0 = <0x00>;
				nvidia,current_dram_clktree_c0d0u1 = <0x00>;
				nvidia,current_dram_clktree_c0d1u0 = <0x00>;
				nvidia,current_dram_clktree_c0d1u1 = <0x00>;
				nvidia,current_dram_clktree_c1d0u0 = <0x00>;
				nvidia,current_dram_clktree_c1d0u1 = <0x00>;
				nvidia,current_dram_clktree_c1d1u0 = <0x00>;
				nvidia,current_dram_clktree_c1d1u1 = <0x00>;
				nvidia,run_clocks = <0x40>;
				nvidia,tree_margin = <0x01>;
				nvidia,burst-regs-num = <0xdd>;
				nvidia,burst-regs-per-ch-num = <0x08>;
				nvidia,trim-regs-num = <0x8a>;
				nvidia,trim-regs-per-ch-num = <0x0a>;
				nvidia,burst-mc-regs-num = <0x21>;
				nvidia,la-scale-regs-num = <0x18>;
				nvidia,vref-regs-num = <0x04>;
				nvidia,training-mod-regs-num = <0x14>;
				nvidia,dram-timing-regs-num = <0x05>;
				nvidia,min-mrs-wait = <0x30>;
				nvidia,emc-mrw = <0x88010054>;
				nvidia,emc-mrw2 = <0x8802002d>;
				nvidia,emc-mrw3 = <0x880d0000>;
				nvidia,emc-mrw4 = <0xc0000000>;
				nvidia,emc-mrw9 = <0x8c0e4848>;
				nvidia,emc-mrs = <0x00>;
				nvidia,emc-emrs = <0x00>;
				nvidia,emc-emrs2 = <0x00>;
				nvidia,emc-auto-cal-config = <0xa01a51d8>;
				nvidia,emc-auto-cal-config2 = <0x5500000>;
				nvidia,emc-auto-cal-config3 = <0x770000>;
				nvidia,emc-auto-cal-config4 = <0x770000>;
				nvidia,emc-auto-cal-config5 = <0x770000>;
				nvidia,emc-auto-cal-config6 = <0x770000>;
				nvidia,emc-auto-cal-config7 = <0x770000>;
				nvidia,emc-auto-cal-config8 = <0x770000>;
				nvidia,emc-cfg-2 = <0x110835>;
				nvidia,emc-sel-dpd-ctrl = <0x40000>;
				nvidia,emc-fdpd-ctrl-cmd-no-ramp = <0x01>;
				nvidia,dll-clk-src = <0x80188000>;
				nvidia,clk-out-enb-x-0-clk-enb-emc-dll = <0x00>;
				nvidia,emc-clock-latency-change = <0x49c>;
				nvidia,ptfv = <0x00 0x00 0x00 0x00 0x00 0x00 0x00 0x00 0x0a 0x0a 0x0a 0x01>;
				nvidia,emc-registers = <0x66 0x1c0 0xe0 0x00 0x00 0x47 0x20 0x2b 0x21 0x0c 0x2d 0x00 0x04 0x20 0x20 0x20 0x13 0x17 0x16 0x06 0x0e 0x0c 0x0a 0x0e 0x08 0x0d 0x24 0x08 0x1000001c 0x10000002 0x14 0x8803f1f1 0x1c 0x01 0x80000000 0x6000c 0x33 0x3b 0x3d 0x39 0x3b 0x5e9 0x00 0x17a 0x10 0x10 0x03 0x03 0x03 0x38 0x0e 0x02 0x31 0x1cc 0x1cc 0x0d 0x18 0x0c 0x40 0x25 0x04 0x14 0xc803f1f1 0x1860 0x00 0x9960a00d 0x3bff 0xc00001bb 0x8000 0x55 0x00 0x00 0x00 0x00 0x00 0x00 0x880b6666 0x8000e 0x11000c 0x1c001c 0x1c001c 0x1c001c 0x1c001c 0x07 0x90002 0x1c001c 0x1c001c 0x1c001c 0x1c001c 0x07 0x90002 0xe000e 0x80008 0xc000c 0x110011 0x0e 0x00 0x00 0x00 0x00 0x00 0x00 0x00 0x00 0x00 0x00 0x00 0x00 0x00 0x00 0x00 0x00 0x00 0x00 0x00 0x00 0x00 0x00 0x00 0x00 0x00 0x00 0x00 0x00 0x00 0x00 0x00 0x00 0x00 0x00 0x00 0x00 0x00 0x00 0x00 0x00 0x8020221f 0x220f40f 0x12 0x64000 0x310640 0x6400030 0x1900017 0xc1e0030a 0x1f13612f 0x14 0x80d 0x550 0xf3200000 0x00 0xce6 0x2b 0x00 0x00 0x1b 0x1b 0x20000 0x33 0x00 0x211 0x3000 0x2000000 0x2000101 0x07 0x30808 0x15c00 0x102020 0x1fff1fff 0x00 0x00 0x00 0x34 0x40 0x18000800 0x8000800 0x8000800 0x8000800 0x400080 0x8801004 0x20 0x00 0x00 0x00 0x00 0x00 0x00 0xefff2210 0x00 0x00 0xdcdcdcdc 0xa0a0a0a 0xa0a0a0a 0xa0a0a0a 0x1186190 0x00 0x00 0x3b 0x2b 0x3d 0x88161414 0x33 0x6000c 0x9080 0x7070404 0x40320 0x513801f 0x1f101100 0x14 0x103200 0x1124000 0x1125b6a 0xf081000 0x105800 0x1110fc00 0xf085300 0x105800 0x1114fc00 0x7004300 0x103200 0x55553c5a 0xc8161414>;
				nvidia,emc-burst-regs-per-ch = <0x880c4848 0x880c4848 0xc80c4848 0xc80c4848 0x8c0e4848 0x8c0e4848 0x4c0e4848 0x4c0e4848>;
				nvidia,emc-shadow-regs-ca-train = <0x66 0x1c0 0xe0 0x00 0x00 0x47 0x20 0x2b 0x21 0x0c 0x2d 0x00 0x04 0x20 0x20 0x20 0x13 0x17 0x16 0x06 0x0e 0x0c 0x0a 0x0e 0x08 0x0d 0x24 0x08 0x1000001c 0x10000002 0x14 0x8803f1f1 0x1c 0x01 0x80000000 0x6000c 0x33 0x3b 0x3d 0x39 0x3b 0x5e9 0x00 0x17a 0x10 0x10 0x03 0x03 0x03 0x38 0x0e 0x02 0x31 0x1cc 0x1cc 0x0d 0x18 0x0c 0x40 0x25 0x04 0x14 0xc803f1f1 0x1860 0x00 0x9960a00d 0x3bff 0xc00001bb 0x8000 0x55 0x00 0x00 0x00 0x00 0x00 0x00 0x880b6666 0x8000e 0x11000c 0x1c001c 0x1c001c 0x1c001c 0x1c001c 0x07 0x90002 0x1c001c 0x1c001c 0x1c001c 0x1c001c 0x07 0x90002 0xe000e 0x80008 0xc000c 0x110011 0x0e 0x00 0x00 0x00 0x00 0x00 0x00 0x00 0x00 0x00 0x00 0x00 0x00 0x00 0x00 0x00 0x00 0x00 0x00 0x00 0x00 0x00 0x00 0x00 0x00 0x00 0x00 0x00 0x00 0x00 0x00 0x00 0x00 0x00 0x00 0x00 0x00 0x00 0x00 0x00 0x00 0x8020221f 0x220f40f 0x12 0x64000 0x310640 0x6400030 0x1900017 0xc1e0030a 0x1f13612f 0x14 0x80d 0x550 0xf3200000 0x00 0xce6 0x2b 0x00 0x00 0x1b 0x1b 0x20000 0x8033 0x00 0x200 0x3000 0x2000000 0x2000101 0x07 0x30808 0x15c00 0x102020 0x1fff1fff 0x00 0x00 0x00 0x34 0x40 0x18000800 0x8000800 0x8000800 0x8000800 0x400080 0x8801004 0x20 0x00 0x00 0x00 0x00 0x00 0x00 0xefff2210 0x00 0x00 0xdcdcdcdc 0xa0a0a0a 0xa0a0a0a 0xa0a0a0a 0x1186190 0x01 0x1f 0x41 0x2b 0x43 0x88161414 0x33 0x6000c 0x9080 0x7070404 0x40320 0x513801f 0x1f101100 0x14 0x103200 0x1124000 0x1125b6a 0xf081000 0x105800 0x1110fc00 0xf085300 0x105800 0x1114fc00 0x7004300 0x103200 0x55553c5a 0xc8161414>;
				nvidia,emc-shadow-regs-quse-train = <0x66 0x1c0 0xe0 0x00 0x00 0x47 0x20 0x2a 0x21 0x0c 0x2d 0x00 0x04 0x20 0x20 0x20 0x13 0x11 0x16 0x06 0x0e 0x0c 0x0a 0x0e 0x08 0x0d 0x21 0x02 0x1000001c 0x10000002 0x14 0x8803f1f1 0x1b 0x01 0x80000000 0x6000c 0x33 0x3b 0x3d 0x39 0x3b 0x5e9 0x00 0x17a 0x10 0x10 0x03 0x03 0x03 0x38 0x0e 0x02 0x31 0x1cc 0x1cc 0x0d 0x18 0x0c 0x40 0x25 0x04 0x14 0xc803f1f1 0x1860 0x00 0x9960400d 0x3bff 0xc00001bb 0x8000 0x55 0x00 0x00 0x00 0x00 0x00 0x00 0x880b6666 0x8000e 0x11000c 0x1c001c 0x1c001c 0x1c001c 0x1c001c 0x07 0x90002 0x1c001c 0x1c001c 0x1c001c 0x1c001c 0x07 0x90002 0xe000e 0x80008 0xc000c 0x110011 0x0e 0x00 0x00 0x00 0x00 0x00 0x00 0x00 0x00 0x00 0x00 0x00 0x00 0x00 0x00 0x00 0x00 0x00 0x00 0x00 0x00 0x00 0x00 0x00 0x00 0x00 0x00 0x00 0x00 0x00 0x00 0x00 0x00 0x00 0x00 0x00 0x00 0x00 0x00 0x00 0x00 0x8020221f 0x220f40f 0x12 0x64000 0x310640 0x6400030 0x1900017 0xc1e0030a 0x1f13612f 0x14 0x80d 0x550 0xf3200000 0x00 0xce6 0x2b 0x00 0x00 0x1b 0x1b 0x30020000 0x8033 0x00 0x211 0x3000 0x2000000 0x2000101 0x07 0x30808 0x15c00 0x102020 0x1fff1fff 0x00 0x00 0x00 0x34 0x40 0x18000800 0x8000800 0x8000800 0x8000800 0x400080 0x8801004 0x20 0x00 0x00 0x00 0x00 0x00 0x00 0xefff2210 0x00 0x00 0xdcdcdcdc 0xa0a0a0a 0xa0a0a0a 0xa0a0a0a 0x1186190 0x01 0x1f 0x45 0x35 0x47 0x88161414 0x3d 0x6000c 0x9080 0x7070404 0x40320 0x513801f 0x1f101100 0x14 0x103200 0x1124000 0x1125b6a 0xf081000 0x105800 0x1110fc00 0xf085300 0x105800 0x1114fc00 0x7004300 0x103200 0x55553c5a 0xc8161414>;
				nvidia,emc-shadow-regs-rdwr-train = <0x66 0x1c0 0xe0 0x00 0x00 0x47 0x20 0x2b 0x21 0x0c 0x2d 0x00 0x04 0x20 0x20 0x20 0x13 0x17 0x16 0x06 0x0e 0x0c 0x0a 0x0e 0x08 0x0d 0x24 0x08 0x1000001c 0x10000002 0x14 0x8803f1f1 0x1c 0x01 0x80000000 0x6000c 0x33 0x3b 0x3d 0x39 0x3b 0x5e9 0x00 0x17a 0x10 0x10 0x03 0x03 0x03 0x38 0x0e 0x02 0x31 0x1cc 0x1cc 0x0d 0x18 0x0c 0x40 0x25 0x04 0x14 0xc803f1f1 0x1860 0x00 0x9960a00d 0x3bff 0xc00001bb 0x8000 0x55 0x00 0x00 0x00 0x00 0x00 0x00 0x880b6666 0x8000e 0x11000c 0x1c001c 0x1c001c 0x1c001c 0x1c001c 0x07 0x90002 0x1c001c 0x1c001c 0x1c001c 0x1c001c 0x07 0x90002 0xe000e 0x80008 0xc000c 0x110011 0x0e 0x00 0x00 0x00 0x00 0x00 0x00 0x00 0x00 0x00 0x00 0x00 0x00 0x00 0x00 0x00 0x00 0x00 0x00 0x00 0x00 0x00 0x00 0x00 0x00 0x00 0x00 0x00 0x00 0x00 0x00 0x00 0x00 0x00 0x00 0x00 0x00 0x00 0x00 0x00 0x00 0x8020221f 0x220f40f 0x12 0x64000 0x310640 0x6400030 0x1900017 0xc1e0030a 0x1f13612f 0x14 0x80d 0x550 0xf3200000 0x00 0xce6 0x2b 0x00 0x00 0x1b 0x1b 0x20000 0x33 0x00 0x211 0x3000 0x2000000 0x2000101 0x07 0x30808 0x15c00 0x102020 0x1fff1fff 0x00 0x00 0x00 0x34 0x40 0x18000800 0x8000800 0x8000800 0x8000800 0x400080 0x8801004 0x20 0x00 0x00 0x00 0x00 0x00 0x00 0xefff2210 0x00 0x00 0xdcdcdcdc 0xa0a0a0a 0xa0a0a0a 0xa0a0a0a 0x1186190 0x01 0x00 0x3b 0x2b 0x3d 0x88161414 0x33 0x6000c 0xb080 0x7070404 0x40320 0x513801f 0x1f101100 0x14 0x103200 0x1124000 0x1125b6a 0xf081000 0x105800 0x1110fc00 0xf085300 0x105800 0x1114fc00 0x7004300 0x103200 0x55553c5a 0xc8161414>;
				nvidia,emc-trim-regs = <0x200020 0x200020 0x200020 0x200020 0x200020 0x200020 0x200020 0x200020 0x00 0x00 0x00 0x00 0x00 0x00 0x00 0x00 0x00 0x00 0x00 0x00 0x00 0x00 0x00 0x00 0x00 0x00 0x00 0x00 0x00 0x00 0x00 0x00 0x00 0x00 0x00 0x00 0x00 0x00 0x00 0x00 0x00 0x00 0x00 0x00 0x00 0x00 0x00 0x00 0x00 0x00 0x00 0x00 0x00 0x00 0x00 0x00 0x17171717 0x17171717 0x11111111 0x11111111 0x2b0022 0x2b0026 0x260025 0x260026 0x8000e 0x11000c 0x2b0022 0x2b0026 0x260025 0x260026 0x00 0x00 0x00 0x00 0x00 0x00 0x00 0x00 0x00 0x00 0x00 0x00 0x00 0x00 0x00 0x00 0x00 0x00 0x00 0x00 0x00 0x00 0x00 0x00 0x00 0x00 0x00 0x00 0x00 0x00 0x00 0x00 0x00 0x00 0x00 0x00 0x00 0x00 0x00 0x00 0x00 0x00 0x00 0x00 0x00 0x00 0x00 0x00 0x00 0x00 0x00 0x00 0x00 0x00 0x00 0x00 0x00 0x00 0x00 0x00 0x00 0x00 0x00 0x00 0x00 0x00 0x00 0x00>;
				nvidia,emc-trim-regs-per-ch = <0x00 0x00 0x00 0x00 0x00 0x00 0x00 0x00 0x00 0x00>;
				nvidia,emc-vref-regs = <0x00 0x00 0x00 0x00>;
				nvidia,emc-dram-timing-regs = <0x13 0x104 0x118 0x07 0x20>;
				nvidia,emc-training-mod-regs = <0x00 0x00 0x00 0x00 0x00 0x00 0x00 0x00 0x00 0x00 0x00 0x00 0x00 0x00 0x00 0x00 0x00 0x00 0x00 0x00>;
				nvidia,emc-save-restore-mod-regs = <0x00 0x00 0x00 0x00 0x00 0x00 0x00 0x00 0x04 0x04 0x04 0x04>;
				nvidia,emc-burst-mc-regs = <0x0c 0x80000080 0xa1020 0x80001028 0x06 0x07 0x19 0x10 0x0f 0x04 0x03 0x0e 0x01 0x01 0x0c 0x08 0x0a 0x37 0x5060000 0xe090c 0x726c241a 0x70000f0f 0x00 0x1f0000 0x80001a 0x80001a 0x80001a 0x80001a 0x80001a 0x80001a 0x80001a 0x80001a 0x80001a>;
				nvidia,emc-la-scale-regs = <0xd0 0x80001a 0x1203 0x80003d 0x800038 0x800041 0x800090 0x800005 0x800090 0x800005 0x340049 0x800080 0x800004 0x80016 0x80 0x800004 0x800019 0x800019 0x800018 0x800095 0x80001d 0x80 0x2c 0x800080>;
			};
		};
	};
};
